VERSION ""

NS_ :

BS_:

BU_: Upper BMS
VAL_TABLE_ operation 132 "操作断路器" 129 "操作继电器" ;
VAL_TABLE_ disable_value 1 "禁止" 0 "允许" ;
VAL_TABLE_ alarm_level2 1 "故障" 0 "正常" ;
VAL_TABLE_ alarm_level 3 "三级告警" 2 "二级告警" 1 "一级故障" 0 "正常" ;
VAL_TABLE_ relay_sts 1 "闭合" 0 "断开" ;
VAL_TABLE_ sys_status 2 "充电" 1 "放电" 0 "空闲" ;

BO_ 2550202728 vol_msg104: 8 BMS
 SG_ cell_vol416 : 48|16@1+ (1,0) [0|65535] "mV" Vector__XXX
 SG_ cell_vol415 : 32|16@1+ (1,0) [0|65535] "mV" Vector__XXX
 SG_ cell_vol414 : 16|16@1+ (1,0) [0|65535] "mV" Vector__XXX
 SG_ cell_vol413 : 0|16@1+ (1,0) [0|65535] "mV" Vector__XXX

BO_ 2550202727 vol_msg103: 8 BMS
 SG_ cell_vol412 : 48|16@1+ (1,0) [0|65535] "mV" Vector__XXX
 SG_ cell_vol411 : 32|16@1+ (1,0) [0|65535] "mV" Vector__XXX
 SG_ cell_vol410 : 16|16@1+ (1,0) [0|65535] "mV" Vector__XXX
 SG_ cell_vol409 : 0|16@1+ (1,0) [0|65535] "mV" Vector__XXX

BO_ 2550202726 vol_msg102: 8 BMS
 SG_ cell_vol408 : 48|16@1+ (1,0) [0|65535] "mV" Vector__XXX
 SG_ cell_vol407 : 32|16@1+ (1,0) [0|65535] "mV" Vector__XXX
 SG_ cell_vol406 : 16|16@1+ (1,0) [0|65535] "mV" Vector__XXX
 SG_ cell_vol405 : 0|16@1+ (1,0) [0|65535] "mV" Vector__XXX

BO_ 2550202725 vol_msg101: 8 BMS
 SG_ cell_vol404 : 48|16@1+ (1,0) [0|65535] "mV" Vector__XXX
 SG_ cell_vol403 : 32|16@1+ (1,0) [0|65535] "mV" Vector__XXX
 SG_ cell_vol402 : 16|16@1+ (1,0) [0|65535] "mV" Vector__XXX
 SG_ cell_vol401 : 0|16@1+ (1,0) [0|65535] "mV" Vector__XXX

BO_ 2550203137 packvol_msg001: 8 Vector__XXX
 SG_ pack_vol4 : 48|16@1+ (10,0) [0|655350] "mV" Vector__XXX
 SG_ pack_vol3 : 32|16@1+ (10,0) [0|655350] "mV" Vector__XXX
 SG_ pack_vol2 : 16|16@1+ (10,0) [0|655350] "mV" Vector__XXX
 SG_ pack_vol1 : 0|16@1+ (10,0) [0|655350] "mV" Vector__XXX

BO_ 2550202383 important_msg15: 8 Vector__XXX
 SG_ bmu_err_id : 0|32@1- (1,0) [0|0] "" Vector__XXX
 SG_ DO_status : 56|1@1- (1,0) [0|0] "" Vector__XXX
 SG_ DI_status : 48|8@1- (1,0) [0|0] "" Vector__XXX

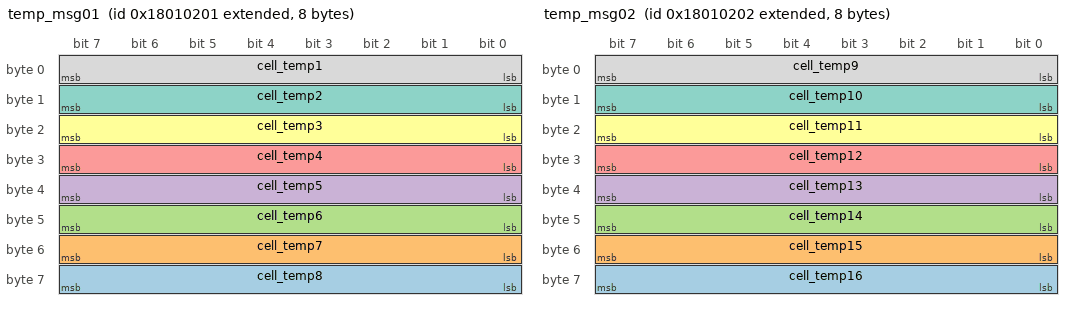
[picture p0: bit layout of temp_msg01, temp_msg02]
BO_ 2550202881 temp_msg01: 8 BMS
 SG_ cell_temp8 : 56|8@1+ (1,-40) [-40|215] "℃" Vector__XXX
 SG_ cell_temp7 : 48|8@1+ (1,-40) [-40|215] "℃" Vector__XXX
 SG_ cell_temp6 : 40|8@1+ (1,-40) [-40|215] "℃" Vector__XXX
 SG_ cell_temp5 : 32|8@1+ (1,-40) [-40|215] "℃" Vector__XXX
 SG_ cell_temp4 : 24|8@1+ (1,-40) [-40|215] "℃" Vector__XXX
 SG_ cell_temp3 : 16|8@1+ (1,-40) [-40|215] "℃" Vector__XXX
 SG_ cell_temp2 : 8|8@1+ (1,-40) [-40|215] "℃" Vector__XXX
 SG_ cell_temp1 : 0|8@1+ (1,-40) [-40|215] "℃" Vector__XXX

BO_ 2550202882 temp_msg02: 8 BMS
 SG_ cell_temp16 : 56|8@1+ (1,-40) [-40|215] "℃" Vector__XXX
 SG_ cell_temp15 : 48|8@1+ (1,-40) [-40|215] "℃" Vector__XXX
 SG_ cell_temp14 : 40|8@1+ (1,-40) [-40|215] "℃" Vector__XXX
 SG_ cell_temp13 : 32|8@1+ (1,-40) [-40|215] "℃" Vector__XXX
 SG_ cell_temp12 : 24|8@1+ (1,-40) [-40|215] "℃" Vector__XXX
 SG_ cell_temp11 : 16|8@1+ (1,-40) [-40|215] "℃" Vector__XXX
 SG_ cell_temp10 : 8|8@1+ (1,-40) [-40|215] "℃" Vector__XXX
 SG_ cell_temp9 : 0|8@1+ (1,-40) [-40|215] "℃" Vector__XXX

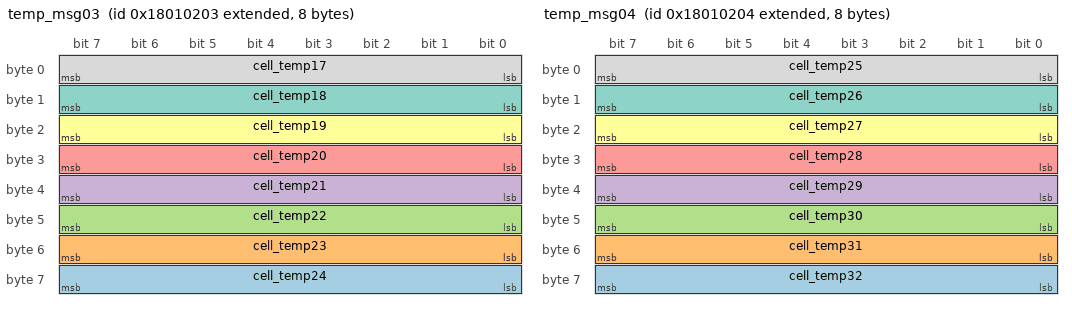
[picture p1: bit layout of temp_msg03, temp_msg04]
BO_ 2550202883 temp_msg03: 8 BMS
 SG_ cell_temp24 : 56|8@1+ (1,-40) [-40|215] "℃" Vector__XXX
 SG_ cell_temp23 : 48|8@1+ (1,-40) [-40|215] "℃" Vector__XXX
 SG_ cell_temp22 : 40|8@1+ (1,-40) [-40|215] "℃" Vector__XXX
 SG_ cell_temp21 : 32|8@1+ (1,-40) [-40|215] "℃" Vector__XXX
 SG_ cell_temp20 : 24|8@1+ (1,-40) [-40|215] "℃" Vector__XXX
 SG_ cell_temp19 : 16|8@1+ (1,-40) [-40|215] "℃" Vector__XXX
 SG_ cell_temp18 : 8|8@1+ (1,-40) [-40|215] "℃" Vector__XXX
 SG_ cell_temp17 : 0|8@1+ (1,-40) [-40|215] "℃" Vector__XXX

BO_ 2550202884 temp_msg04: 8 BMS
 SG_ cell_temp32 : 56|8@1+ (1,-40) [-40|215] "℃" Vector__XXX
 SG_ cell_temp31 : 48|8@1+ (1,-40) [-40|215] "℃" Vector__XXX
 SG_ cell_temp30 : 40|8@1+ (1,-40) [-40|215] "℃" Vector__XXX
 SG_ cell_temp29 : 32|8@1+ (1,-40) [-40|215] "℃" Vector__XXX
 SG_ cell_temp28 : 24|8@1+ (1,-40) [-40|215] "℃" Vector__XXX
 SG_ cell_temp27 : 16|8@1+ (1,-40) [-40|215] "℃" Vector__XXX
 SG_ cell_temp26 : 8|8@1+ (1,-40) [-40|215] "℃" Vector__XXX
 SG_ cell_temp25 : 0|8@1+ (1,-40) [-40|215] "℃" Vector__XXX

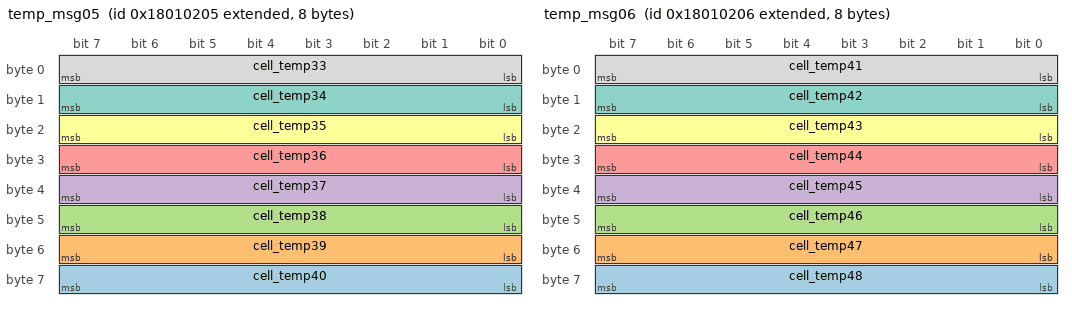
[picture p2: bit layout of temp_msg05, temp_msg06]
BO_ 2550202885 temp_msg05: 8 BMS
 SG_ cell_temp40 : 56|8@1+ (1,-40) [-40|215] "℃" Vector__XXX
 SG_ cell_temp39 : 48|8@1+ (1,-40) [-40|215] "℃" Vector__XXX
 SG_ cell_temp38 : 40|8@1+ (1,-40) [-40|215] "℃" Vector__XXX
 SG_ cell_temp37 : 32|8@1+ (1,-40) [-40|215] "℃" Vector__XXX
 SG_ cell_temp36 : 24|8@1+ (1,-40) [-40|215] "℃" Vector__XXX
 SG_ cell_temp35 : 16|8@1+ (1,-40) [-40|215] "℃" Vector__XXX
 SG_ cell_temp34 : 8|8@1+ (1,-40) [-40|215] "℃" Vector__XXX
 SG_ cell_temp33 : 0|8@1+ (1,-40) [-40|215] "℃" Vector__XXX

BO_ 2550202886 temp_msg06: 8 BMS
 SG_ cell_temp48 : 56|8@1+ (1,-40) [-40|215] "℃" Vector__XXX
 SG_ cell_temp47 : 48|8@1+ (1,-40) [-40|215] "℃" Vector__XXX
 SG_ cell_temp46 : 40|8@1+ (1,-40) [-40|215] "℃" Vector__XXX
 SG_ cell_temp45 : 32|8@1+ (1,-40) [-40|215] "℃" Vector__XXX
 SG_ cell_temp44 : 24|8@1+ (1,-40) [-40|215] "℃" Vector__XXX
 SG_ cell_temp43 : 16|8@1+ (1,-40) [-40|215] "℃" Vector__XXX
 SG_ cell_temp42 : 8|8@1+ (1,-40) [-40|215] "℃" Vector__XXX
 SG_ cell_temp41 : 0|8@1+ (1,-40) [-40|215] "℃" Vector__XXX

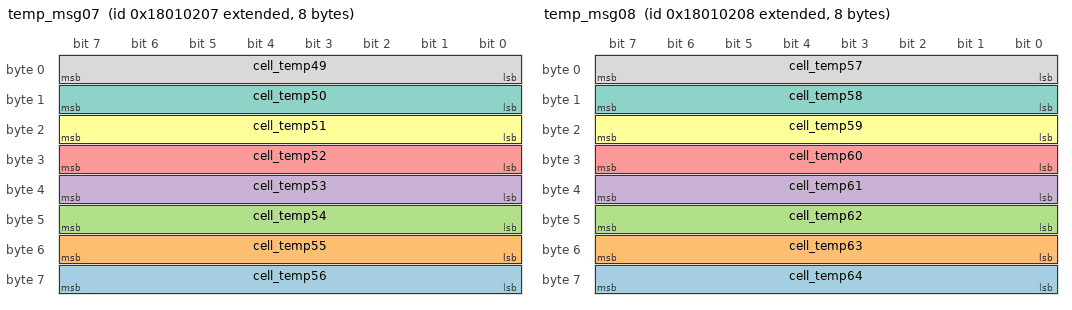
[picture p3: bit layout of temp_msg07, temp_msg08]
BO_ 2550202887 temp_msg07: 8 BMS
 SG_ cell_temp56 : 56|8@1+ (1,-40) [-40|215] "℃" Vector__XXX
 SG_ cell_temp55 : 48|8@1+ (1,-40) [-40|215] "℃" Vector__XXX
 SG_ cell_temp54 : 40|8@1+ (1,-40) [-40|215] "℃" Vector__XXX
 SG_ cell_temp53 : 32|8@1+ (1,-40) [-40|215] "℃" Vector__XXX
 SG_ cell_temp52 : 24|8@1+ (1,-40) [-40|215] "℃" Vector__XXX
 SG_ cell_temp51 : 16|8@1+ (1,-40) [-40|215] "℃" Vector__XXX
 SG_ cell_temp50 : 8|8@1+ (1,-40) [-40|215] "℃" Vector__XXX
 SG_ cell_temp49 : 0|8@1+ (1,-40) [-40|215] "℃" Vector__XXX

BO_ 2550202888 temp_msg08: 8 BMS
 SG_ cell_temp64 : 56|8@1+ (1,-40) [-40|215] "℃" Vector__XXX
 SG_ cell_temp63 : 48|8@1+ (1,-40) [-40|215] "℃" Vector__XXX
 SG_ cell_temp62 : 40|8@1+ (1,-40) [-40|215] "℃" Vector__XXX
 SG_ cell_temp61 : 32|8@1+ (1,-40) [-40|215] "℃" Vector__XXX
 SG_ cell_temp60 : 24|8@1+ (1,-40) [-40|215] "℃" Vector__XXX
 SG_ cell_temp59 : 16|8@1+ (1,-40) [-40|215] "℃" Vector__XXX
 SG_ cell_temp58 : 8|8@1+ (1,-40) [-40|215] "℃" Vector__XXX
 SG_ cell_temp57 : 0|8@1+ (1,-40) [-40|215] "℃" Vector__XXX

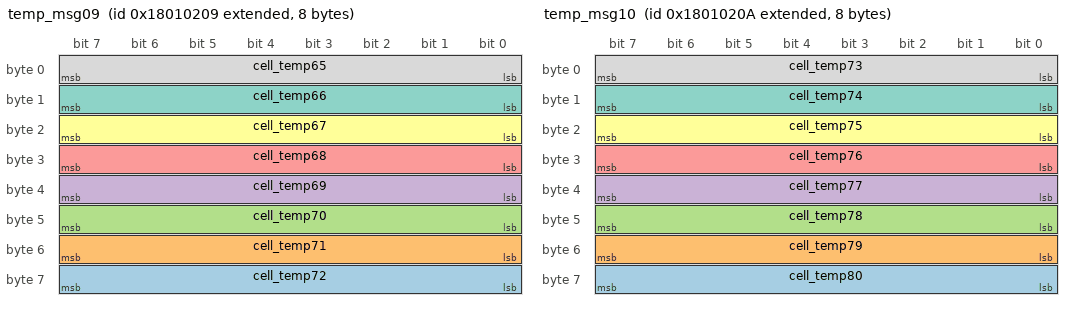
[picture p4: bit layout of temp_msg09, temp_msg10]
BO_ 2550202889 temp_msg09: 8 BMS
 SG_ cell_temp72 : 56|8@1+ (1,-40) [-40|215] "℃" Vector__XXX
 SG_ cell_temp71 : 48|8@1+ (1,-40) [-40|215] "℃" Vector__XXX
 SG_ cell_temp70 : 40|8@1+ (1,-40) [-40|215] "℃" Vector__XXX
 SG_ cell_temp69 : 32|8@1+ (1,-40) [-40|215] "℃" Vector__XXX
 SG_ cell_temp68 : 24|8@1+ (1,-40) [-40|215] "℃" Vector__XXX
 SG_ cell_temp67 : 16|8@1+ (1,-40) [-40|215] "℃" Vector__XXX
 SG_ cell_temp66 : 8|8@1+ (1,-40) [-40|215] "℃" Vector__XXX
 SG_ cell_temp65 : 0|8@1+ (1,-40) [-40|215] "℃" Vector__XXX

BO_ 2550202890 temp_msg10: 8 BMS
 SG_ cell_temp80 : 56|8@1+ (1,-40) [-40|215] "℃" Vector__XXX
 SG_ cell_temp79 : 48|8@1+ (1,-40) [-40|215] "℃" Vector__XXX
 SG_ cell_temp78 : 40|8@1+ (1,-40) [-40|215] "℃" Vector__XXX
 SG_ cell_temp77 : 32|8@1+ (1,-40) [-40|215] "℃" Vector__XXX
 SG_ cell_temp76 : 24|8@1+ (1,-40) [-40|215] "℃" Vector__XXX
 SG_ cell_temp75 : 16|8@1+ (1,-40) [-40|215] "℃" Vector__XXX
 SG_ cell_temp74 : 8|8@1+ (1,-40) [-40|215] "℃" Vector__XXX
 SG_ cell_temp73 : 0|8@1+ (1,-40) [-40|215] "℃" Vector__XXX

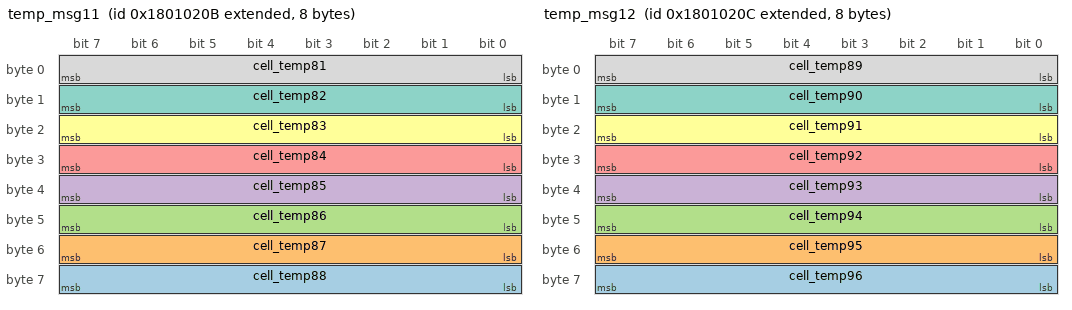
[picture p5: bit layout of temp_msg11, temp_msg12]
BO_ 2550202891 temp_msg11: 8 BMS
 SG_ cell_temp88 : 56|8@1+ (1,-40) [-40|215] "℃" Vector__XXX
 SG_ cell_temp87 : 48|8@1+ (1,-40) [-40|215] "℃" Vector__XXX
 SG_ cell_temp86 : 40|8@1+ (1,-40) [-40|215] "℃" Vector__XXX
 SG_ cell_temp85 : 32|8@1+ (1,-40) [-40|215] "℃" Vector__XXX
 SG_ cell_temp84 : 24|8@1+ (1,-40) [-40|215] "℃" Vector__XXX
 SG_ cell_temp83 : 16|8@1+ (1,-40) [-40|215] "℃" Vector__XXX
 SG_ cell_temp82 : 8|8@1+ (1,-40) [-40|215] "℃" Vector__XXX
 SG_ cell_temp81 : 0|8@1+ (1,-40) [-40|215] "℃" Vector__XXX

BO_ 2550202892 temp_msg12: 8 BMS
 SG_ cell_temp96 : 56|8@1+ (1,-40) [-40|215] "℃" Vector__XXX
 SG_ cell_temp95 : 48|8@1+ (1,-40) [-40|215] "℃" Vector__XXX
 SG_ cell_temp94 : 40|8@1+ (1,-40) [-40|215] "℃" Vector__XXX
 SG_ cell_temp93 : 32|8@1+ (1,-40) [-40|215] "℃" Vector__XXX
 SG_ cell_temp92 : 24|8@1+ (1,-40) [-40|215] "℃" Vector__XXX
 SG_ cell_temp91 : 16|8@1+ (1,-40) [-40|215] "℃" Vector__XXX
 SG_ cell_temp90 : 8|8@1+ (1,-40) [-40|215] "℃" Vector__XXX
 SG_ cell_temp89 : 0|8@1+ (1,-40) [-40|215] "℃" Vector__XXX

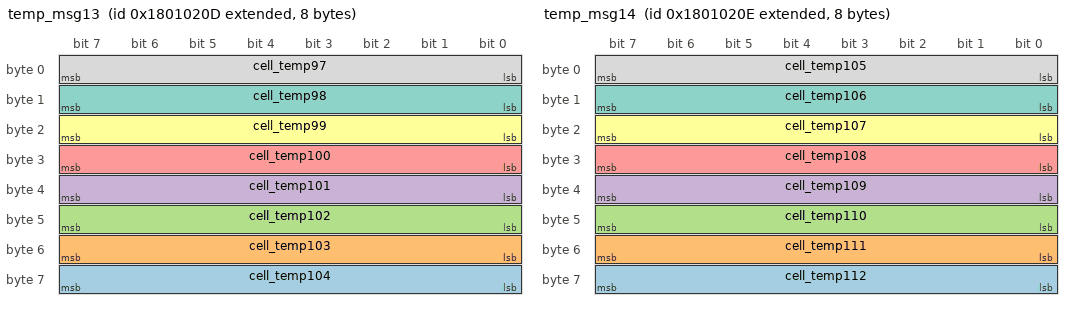
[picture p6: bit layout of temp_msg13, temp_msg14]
BO_ 2550202893 temp_msg13: 8 BMS
 SG_ cell_temp104 : 56|8@1+ (1,-40) [-40|215] "℃" Vector__XXX
 SG_ cell_temp103 : 48|8@1+ (1,-40) [-40|215] "℃" Vector__XXX
 SG_ cell_temp102 : 40|8@1+ (1,-40) [-40|215] "℃" Vector__XXX
 SG_ cell_temp101 : 32|8@1+ (1,-40) [-40|215] "℃" Vector__XXX
 SG_ cell_temp100 : 24|8@1+ (1,-40) [-40|215] "℃" Vector__XXX
 SG_ cell_temp99 : 16|8@1+ (1,-40) [-40|215] "℃" Vector__XXX
 SG_ cell_temp98 : 8|8@1+ (1,-40) [-40|215] "℃" Vector__XXX
 SG_ cell_temp97 : 0|8@1+ (1,-40) [-40|215] "℃" Vector__XXX

BO_ 2550202894 temp_msg14: 8 BMS
 SG_ cell_temp112 : 56|8@1+ (1,-40) [-40|215] "℃" Vector__XXX
 SG_ cell_temp111 : 48|8@1+ (1,-40) [-40|215] "℃" Vector__XXX
 SG_ cell_temp110 : 40|8@1+ (1,-40) [-40|215] "℃" Vector__XXX
 SG_ cell_temp109 : 32|8@1+ (1,-40) [-40|215] "℃" Vector__XXX
 SG_ cell_temp108 : 24|8@1+ (1,-40) [-40|215] "℃" Vector__XXX
 SG_ cell_temp107 : 16|8@1+ (1,-40) [-40|215] "℃" Vector__XXX
 SG_ cell_temp106 : 8|8@1+ (1,-40) [-40|215] "℃" Vector__XXX
 SG_ cell_temp105 : 0|8@1+ (1,-40) [-40|215] "℃" Vector__XXX

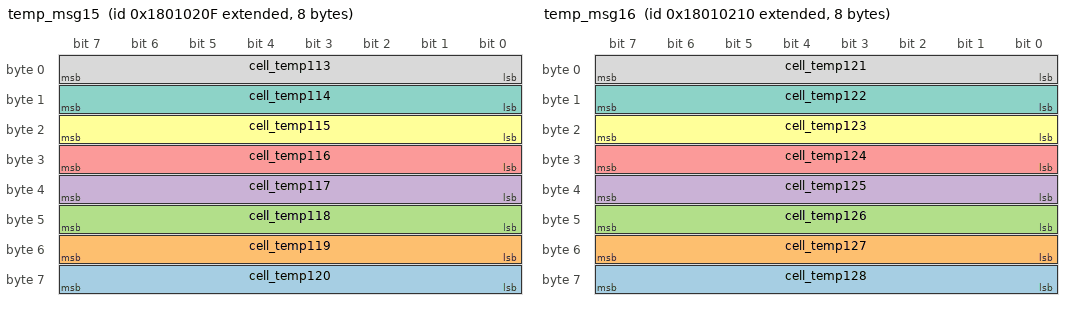
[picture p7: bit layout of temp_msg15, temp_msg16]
BO_ 2550202895 temp_msg15: 8 BMS
 SG_ cell_temp120 : 56|8@1+ (1,-40) [-40|215] "℃" Vector__XXX
 SG_ cell_temp119 : 48|8@1+ (1,-40) [-40|215] "℃" Vector__XXX
 SG_ cell_temp118 : 40|8@1+ (1,-40) [-40|215] "℃" Vector__XXX
 SG_ cell_temp117 : 32|8@1+ (1,-40) [-40|215] "℃" Vector__XXX
 SG_ cell_temp116 : 24|8@1+ (1,-40) [-40|215] "℃" Vector__XXX
 SG_ cell_temp115 : 16|8@1+ (1,-40) [-40|215] "℃" Vector__XXX
 SG_ cell_temp114 : 8|8@1+ (1,-40) [-40|215] "℃" Vector__XXX
 SG_ cell_temp113 : 0|8@1+ (1,-40) [-40|215] "℃" Vector__XXX

BO_ 2550202896 temp_msg16: 8 BMS
 SG_ cell_temp128 : 56|8@1+ (1,-40) [-40|215] "℃" Vector__XXX
 SG_ cell_temp127 : 48|8@1+ (1,-40) [-40|215] "℃" Vector__XXX
 SG_ cell_temp126 : 40|8@1+ (1,-40) [-40|215] "℃" Vector__XXX
 SG_ cell_temp125 : 32|8@1+ (1,-40) [-40|215] "℃" Vector__XXX
 SG_ cell_temp124 : 24|8@1+ (1,-40) [-40|215] "℃" Vector__XXX
 SG_ cell_temp123 : 16|8@1+ (1,-40) [-40|215] "℃" Vector__XXX
 SG_ cell_temp122 : 8|8@1+ (1,-40) [-40|215] "℃" Vector__XXX
 SG_ cell_temp121 : 0|8@1+ (1,-40) [-40|215] "℃" Vector__XXX

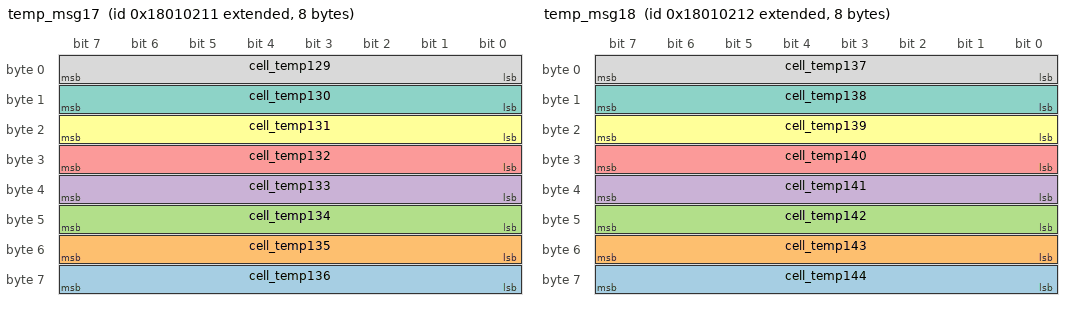
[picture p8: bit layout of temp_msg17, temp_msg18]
BO_ 2550202897 temp_msg17: 8 BMS
 SG_ cell_temp136 : 56|8@1+ (1,-40) [-40|215] "℃" Vector__XXX
 SG_ cell_temp135 : 48|8@1+ (1,-40) [-40|215] "℃" Vector__XXX
 SG_ cell_temp134 : 40|8@1+ (1,-40) [-40|215] "℃" Vector__XXX
 SG_ cell_temp133 : 32|8@1+ (1,-40) [-40|215] "℃" Vector__XXX
 SG_ cell_temp132 : 24|8@1+ (1,-40) [-40|215] "℃" Vector__XXX
 SG_ cell_temp131 : 16|8@1+ (1,-40) [-40|215] "℃" Vector__XXX
 SG_ cell_temp130 : 8|8@1+ (1,-40) [-40|215] "℃" Vector__XXX
 SG_ cell_temp129 : 0|8@1+ (1,-40) [-40|215] "℃" Vector__XXX

BO_ 2550202898 temp_msg18: 8 BMS
 SG_ cell_temp144 : 56|8@1+ (1,-40) [-40|215] "℃" Vector__XXX
 SG_ cell_temp143 : 48|8@1+ (1,-40) [-40|215] "℃" Vector__XXX
 SG_ cell_temp142 : 40|8@1+ (1,-40) [-40|215] "℃" Vector__XXX
 SG_ cell_temp141 : 32|8@1+ (1,-40) [-40|215] "℃" Vector__XXX
 SG_ cell_temp140 : 24|8@1+ (1,-40) [-40|215] "℃" Vector__XXX
 SG_ cell_temp139 : 16|8@1+ (1,-40) [-40|215] "℃" Vector__XXX
 SG_ cell_temp138 : 8|8@1+ (1,-40) [-40|215] "℃" Vector__XXX
 SG_ cell_temp137 : 0|8@1+ (1,-40) [-40|215] "℃" Vector__XXX

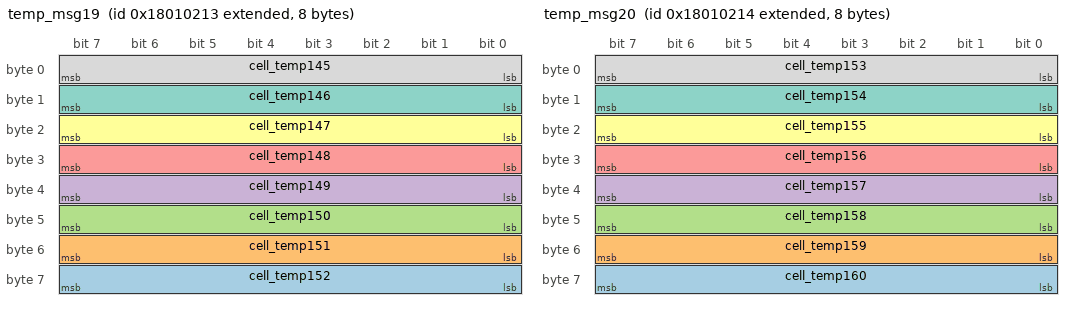
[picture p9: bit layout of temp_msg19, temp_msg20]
BO_ 2550202899 temp_msg19: 8 BMS
 SG_ cell_temp152 : 56|8@1+ (1,-40) [-40|215] "℃" Vector__XXX
 SG_ cell_temp151 : 48|8@1+ (1,-40) [-40|215] "℃" Vector__XXX
 SG_ cell_temp150 : 40|8@1+ (1,-40) [-40|215] "℃" Vector__XXX
 SG_ cell_temp149 : 32|8@1+ (1,-40) [-40|215] "℃" Vector__XXX
 SG_ cell_temp148 : 24|8@1+ (1,-40) [-40|215] "℃" Vector__XXX
 SG_ cell_temp147 : 16|8@1+ (1,-40) [-40|215] "℃" Vector__XXX
 SG_ cell_temp146 : 8|8@1+ (1,-40) [-40|215] "℃" Vector__XXX
 SG_ cell_temp145 : 0|8@1+ (1,-40) [-40|215] "℃" Vector__XXX

BO_ 2550202900 temp_msg20: 8 BMS
 SG_ cell_temp160 : 56|8@1+ (1,-40) [-40|215] "℃" Vector__XXX
 SG_ cell_temp159 : 48|8@1+ (1,-40) [-40|215] "℃" Vector__XXX
 SG_ cell_temp158 : 40|8@1+ (1,-40) [-40|215] "℃" Vector__XXX
 SG_ cell_temp157 : 32|8@1+ (1,-40) [-40|215] "℃" Vector__XXX
 SG_ cell_temp156 : 24|8@1+ (1,-40) [-40|215] "℃" Vector__XXX
 SG_ cell_temp155 : 16|8@1+ (1,-40) [-40|215] "℃" Vector__XXX
 SG_ cell_temp154 : 8|8@1+ (1,-40) [-40|215] "℃" Vector__XXX
 SG_ cell_temp153 : 0|8@1+ (1,-40) [-40|215] "℃" Vector__XXX

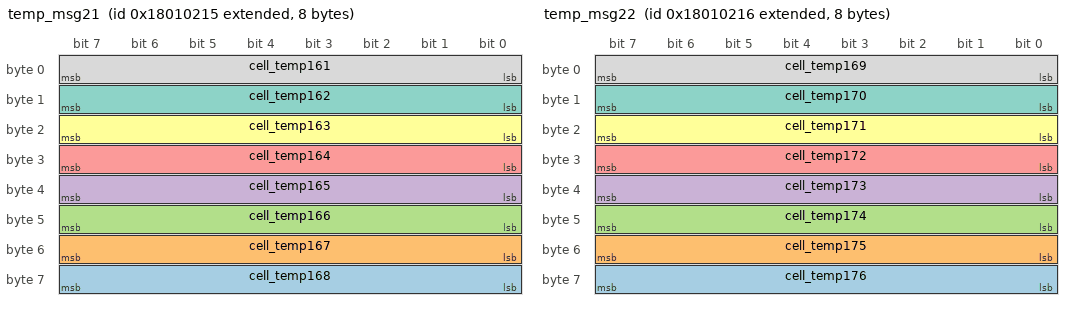
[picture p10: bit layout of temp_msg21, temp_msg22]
BO_ 2550202901 temp_msg21: 8 BMS
 SG_ cell_temp168 : 56|8@1+ (1,-40) [-40|215] "℃" Vector__XXX
 SG_ cell_temp167 : 48|8@1+ (1,-40) [-40|215] "℃" Vector__XXX
 SG_ cell_temp166 : 40|8@1+ (1,-40) [-40|215] "℃" Vector__XXX
 SG_ cell_temp165 : 32|8@1+ (1,-40) [-40|215] "℃" Vector__XXX
 SG_ cell_temp164 : 24|8@1+ (1,-40) [-40|215] "℃" Vector__XXX
 SG_ cell_temp163 : 16|8@1+ (1,-40) [-40|215] "℃" Vector__XXX
 SG_ cell_temp162 : 8|8@1+ (1,-40) [-40|215] "℃" Vector__XXX
 SG_ cell_temp161 : 0|8@1+ (1,-40) [-40|215] "℃" Vector__XXX

BO_ 2550202902 temp_msg22: 8 BMS
 SG_ cell_temp176 : 56|8@1+ (1,-40) [-40|215] "℃" Vector__XXX
 SG_ cell_temp175 : 48|8@1+ (1,-40) [-40|215] "℃" Vector__XXX
 SG_ cell_temp174 : 40|8@1+ (1,-40) [-40|215] "℃" Vector__XXX
 SG_ cell_temp173 : 32|8@1+ (1,-40) [-40|215] "℃" Vector__XXX
 SG_ cell_temp172 : 24|8@1+ (1,-40) [-40|215] "℃" Vector__XXX
 SG_ cell_temp171 : 16|8@1+ (1,-40) [-40|215] "℃" Vector__XXX
 SG_ cell_temp170 : 8|8@1+ (1,-40) [-40|215] "℃" Vector__XXX
 SG_ cell_temp169 : 0|8@1+ (1,-40) [-40|215] "℃" Vector__XXX

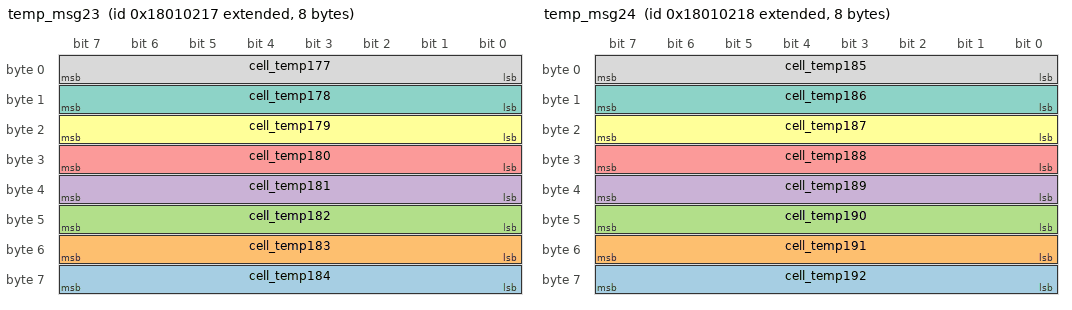
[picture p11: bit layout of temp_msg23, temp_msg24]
BO_ 2550202903 temp_msg23: 8 BMS
 SG_ cell_temp184 : 56|8@1+ (1,-40) [-40|215] "℃" Vector__XXX
 SG_ cell_temp183 : 48|8@1+ (1,-40) [-40|215] "℃" Vector__XXX
 SG_ cell_temp182 : 40|8@1+ (1,-40) [-40|215] "℃" Vector__XXX
 SG_ cell_temp181 : 32|8@1+ (1,-40) [-40|215] "℃" Vector__XXX
 SG_ cell_temp180 : 24|8@1+ (1,-40) [-40|215] "℃" Vector__XXX
 SG_ cell_temp179 : 16|8@1+ (1,-40) [-40|215] "℃" Vector__XXX
 SG_ cell_temp178 : 8|8@1+ (1,-40) [-40|215] "℃" Vector__XXX
 SG_ cell_temp177 : 0|8@1+ (1,-40) [-40|215] "℃" Vector__XXX

BO_ 2550202904 temp_msg24: 8 BMS
 SG_ cell_temp192 : 56|8@1+ (1,-40) [-40|215] "℃" Vector__XXX
 SG_ cell_temp191 : 48|8@1+ (1,-40) [-40|215] "℃" Vector__XXX
 SG_ cell_temp190 : 40|8@1+ (1,-40) [-40|215] "℃" Vector__XXX
 SG_ cell_temp189 : 32|8@1+ (1,-40) [-40|215] "℃" Vector__XXX
 SG_ cell_temp188 : 24|8@1+ (1,-40) [-40|215] "℃" Vector__XXX
 SG_ cell_temp187 : 16|8@1+ (1,-40) [-40|215] "℃" Vector__XXX
 SG_ cell_temp186 : 8|8@1+ (1,-40) [-40|215] "℃" Vector__XXX
 SG_ cell_temp185 : 0|8@1+ (1,-40) [-40|215] "℃" Vector__XXX

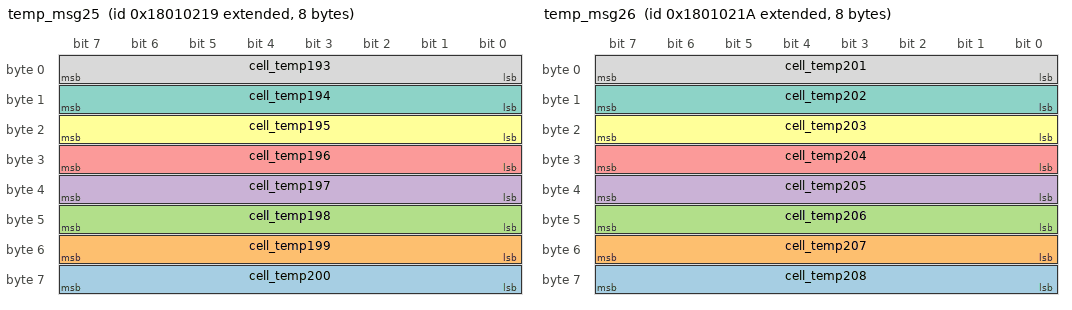
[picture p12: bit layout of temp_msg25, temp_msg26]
BO_ 2550202905 temp_msg25: 8 BMS
 SG_ cell_temp200 : 56|8@1+ (1,-40) [-40|215] "℃" Vector__XXX
 SG_ cell_temp199 : 48|8@1+ (1,-40) [-40|215] "℃" Vector__XXX
 SG_ cell_temp198 : 40|8@1+ (1,-40) [-40|215] "℃" Vector__XXX
 SG_ cell_temp197 : 32|8@1+ (1,-40) [-40|215] "℃" Vector__XXX
 SG_ cell_temp196 : 24|8@1+ (1,-40) [-40|215] "℃" Vector__XXX
 SG_ cell_temp195 : 16|8@1+ (1,-40) [-40|215] "℃" Vector__XXX
 SG_ cell_temp194 : 8|8@1+ (1,-40) [-40|215] "℃" Vector__XXX
 SG_ cell_temp193 : 0|8@1+ (1,-40) [-40|215] "℃" Vector__XXX

BO_ 2550202906 temp_msg26: 8 BMS
 SG_ cell_temp208 : 56|8@1+ (1,-40) [-40|215] "℃" Vector__XXX
 SG_ cell_temp207 : 48|8@1+ (1,-40) [-40|215] "℃" Vector__XXX
 SG_ cell_temp206 : 40|8@1+ (1,-40) [-40|215] "℃" Vector__XXX
 SG_ cell_temp205 : 32|8@1+ (1,-40) [-40|215] "℃" Vector__XXX
 SG_ cell_temp204 : 24|8@1+ (1,-40) [-40|215] "℃" Vector__XXX
 SG_ cell_temp203 : 16|8@1+ (1,-40) [-40|215] "℃" Vector__XXX
 SG_ cell_temp202 : 8|8@1+ (1,-40) [-40|215] "℃" Vector__XXX
 SG_ cell_temp201 : 0|8@1+ (1,-40) [-40|215] "℃" Vector__XXX

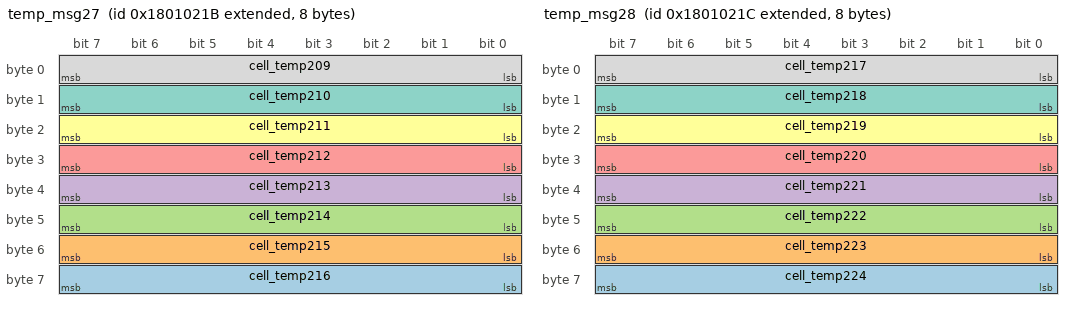
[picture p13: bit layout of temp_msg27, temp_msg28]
BO_ 2550202907 temp_msg27: 8 BMS
 SG_ cell_temp216 : 56|8@1+ (1,-40) [-40|215] "℃" Vector__XXX
 SG_ cell_temp215 : 48|8@1+ (1,-40) [-40|215] "℃" Vector__XXX
 SG_ cell_temp214 : 40|8@1+ (1,-40) [-40|215] "℃" Vector__XXX
 SG_ cell_temp213 : 32|8@1+ (1,-40) [-40|215] "℃" Vector__XXX
 SG_ cell_temp212 : 24|8@1+ (1,-40) [-40|215] "℃" Vector__XXX
 SG_ cell_temp211 : 16|8@1+ (1,-40) [-40|215] "℃" Vector__XXX
 SG_ cell_temp210 : 8|8@1+ (1,-40) [-40|215] "℃" Vector__XXX
 SG_ cell_temp209 : 0|8@1+ (1,-40) [-40|215] "℃" Vector__XXX

BO_ 2550202908 temp_msg28: 8 BMS
 SG_ cell_temp224 : 56|8@1+ (1,-40) [-40|215] "℃" Vector__XXX
 SG_ cell_temp223 : 48|8@1+ (1,-40) [-40|215] "℃" Vector__XXX
 SG_ cell_temp222 : 40|8@1+ (1,-40) [-40|215] "℃" Vector__XXX
 SG_ cell_temp221 : 32|8@1+ (1,-40) [-40|215] "℃" Vector__XXX
 SG_ cell_temp220 : 24|8@1+ (1,-40) [-40|215] "℃" Vector__XXX
 SG_ cell_temp219 : 16|8@1+ (1,-40) [-40|215] "℃" Vector__XXX
 SG_ cell_temp218 : 8|8@1+ (1,-40) [-40|215] "℃" Vector__XXX
 SG_ cell_temp217 : 0|8@1+ (1,-40) [-40|215] "℃" Vector__XXX

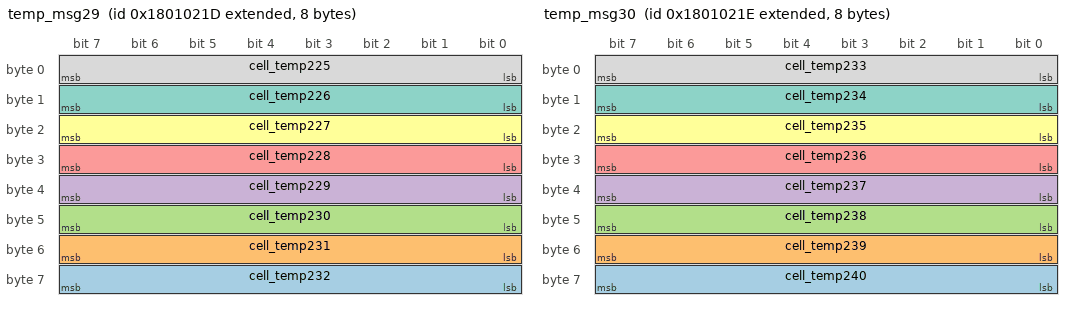
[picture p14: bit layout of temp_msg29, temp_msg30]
BO_ 2550202909 temp_msg29: 8 BMS
 SG_ cell_temp232 : 56|8@1+ (1,-40) [-40|215] "℃" Vector__XXX
 SG_ cell_temp231 : 48|8@1+ (1,-40) [-40|215] "℃" Vector__XXX
 SG_ cell_temp230 : 40|8@1+ (1,-40) [-40|215] "℃" Vector__XXX
 SG_ cell_temp229 : 32|8@1+ (1,-40) [-40|215] "℃" Vector__XXX
 SG_ cell_temp228 : 24|8@1+ (1,-40) [-40|215] "℃" Vector__XXX
 SG_ cell_temp227 : 16|8@1+ (1,-40) [-40|215] "℃" Vector__XXX
 SG_ cell_temp226 : 8|8@1+ (1,-40) [-40|215] "℃" Vector__XXX
 SG_ cell_temp225 : 0|8@1+ (1,-40) [-40|215] "℃" Vector__XXX

BO_ 2550202910 temp_msg30: 8 BMS
 SG_ cell_temp240 : 56|8@1+ (1,-40) [-40|215] "℃" Vector__XXX
 SG_ cell_temp239 : 48|8@1+ (1,-40) [-40|215] "℃" Vector__XXX
 SG_ cell_temp238 : 40|8@1+ (1,-40) [-40|215] "℃" Vector__XXX
 SG_ cell_temp237 : 32|8@1+ (1,-40) [-40|215] "℃" Vector__XXX
 SG_ cell_temp236 : 24|8@1+ (1,-40) [-40|215] "℃" Vector__XXX
 SG_ cell_temp235 : 16|8@1+ (1,-40) [-40|215] "℃" Vector__XXX
 SG_ cell_temp234 : 8|8@1+ (1,-40) [-40|215] "℃" Vector__XXX
 SG_ cell_temp233 : 0|8@1+ (1,-40) [-40|215] "℃" Vector__XXX

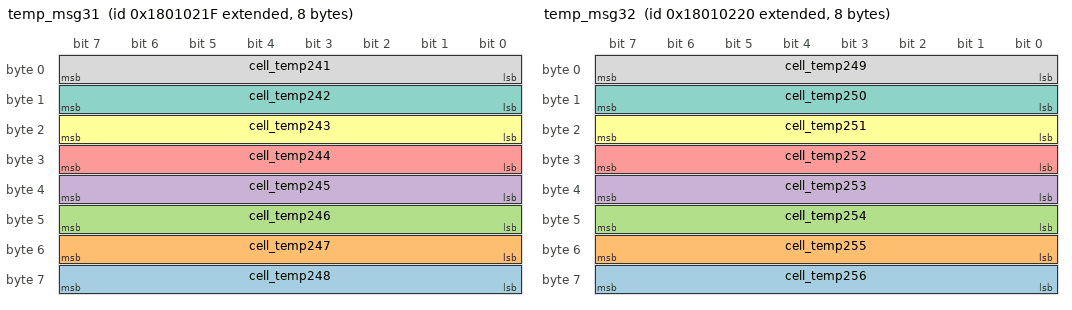
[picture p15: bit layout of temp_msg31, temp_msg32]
BO_ 2550202911 temp_msg31: 8 BMS
 SG_ cell_temp248 : 56|8@1+ (1,-40) [-40|215] "℃" Vector__XXX
 SG_ cell_temp247 : 48|8@1+ (1,-40) [-40|215] "℃" Vector__XXX
 SG_ cell_temp246 : 40|8@1+ (1,-40) [-40|215] "℃" Vector__XXX
 SG_ cell_temp245 : 32|8@1+ (1,-40) [-40|215] "℃" Vector__XXX
 SG_ cell_temp244 : 24|8@1+ (1,-40) [-40|215] "℃" Vector__XXX
 SG_ cell_temp243 : 16|8@1+ (1,-40) [-40|215] "℃" Vector__XXX
 SG_ cell_temp242 : 8|8@1+ (1,-40) [-40|215] "℃" Vector__XXX
 SG_ cell_temp241 : 0|8@1+ (1,-40) [-40|215] "℃" Vector__XXX

BO_ 2550202912 temp_msg32: 8 BMS
 SG_ cell_temp256 : 56|8@1+ (1,-40) [-40|215] "℃" Vector__XXX
 SG_ cell_temp255 : 48|8@1+ (1,-40) [-40|215] "℃" Vector__XXX
 SG_ cell_temp254 : 40|8@1+ (1,-40) [-40|215] "℃" Vector__XXX
 SG_ cell_temp253 : 32|8@1+ (1,-40) [-40|215] "℃" Vector__XXX
 SG_ cell_temp252 : 24|8@1+ (1,-40) [-40|215] "℃" Vector__XXX
 SG_ cell_temp251 : 16|8@1+ (1,-40) [-40|215] "℃" Vector__XXX
 SG_ cell_temp250 : 8|8@1+ (1,-40) [-40|215] "℃" Vector__XXX
 SG_ cell_temp249 : 0|8@1+ (1,-40) [-40|215] "℃" Vector__XXX

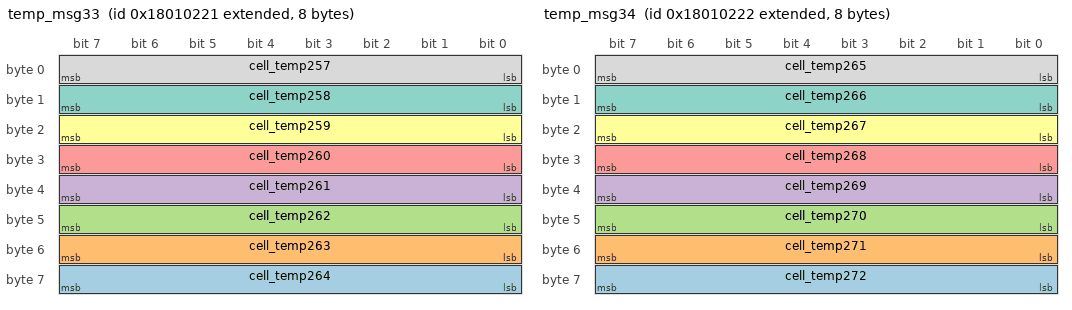
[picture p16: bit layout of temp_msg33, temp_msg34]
BO_ 2550202913 temp_msg33: 8 BMS
 SG_ cell_temp264 : 56|8@1+ (1,-40) [-40|215] "℃" Vector__XXX
 SG_ cell_temp263 : 48|8@1+ (1,-40) [-40|215] "℃" Vector__XXX
 SG_ cell_temp262 : 40|8@1+ (1,-40) [-40|215] "℃" Vector__XXX
 SG_ cell_temp261 : 32|8@1+ (1,-40) [-40|215] "℃" Vector__XXX
 SG_ cell_temp260 : 24|8@1+ (1,-40) [-40|215] "℃" Vector__XXX
 SG_ cell_temp259 : 16|8@1+ (1,-40) [-40|215] "℃" Vector__XXX
 SG_ cell_temp258 : 8|8@1+ (1,-40) [-40|215] "℃" Vector__XXX
 SG_ cell_temp257 : 0|8@1+ (1,-40) [-40|215] "℃" Vector__XXX

BO_ 2550202914 temp_msg34: 8 BMS
 SG_ cell_temp272 : 56|8@1+ (1,-40) [-40|215] "℃" Vector__XXX
 SG_ cell_temp271 : 48|8@1+ (1,-40) [-40|215] "℃" Vector__XXX
 SG_ cell_temp270 : 40|8@1+ (1,-40) [-40|215] "℃" Vector__XXX
 SG_ cell_temp269 : 32|8@1+ (1,-40) [-40|215] "℃" Vector__XXX
 SG_ cell_temp268 : 24|8@1+ (1,-40) [-40|215] "℃" Vector__XXX
 SG_ cell_temp267 : 16|8@1+ (1,-40) [-40|215] "℃" Vector__XXX
 SG_ cell_temp266 : 8|8@1+ (1,-40) [-40|215] "℃" Vector__XXX
 SG_ cell_temp265 : 0|8@1+ (1,-40) [-40|215] "℃" Vector__XXX

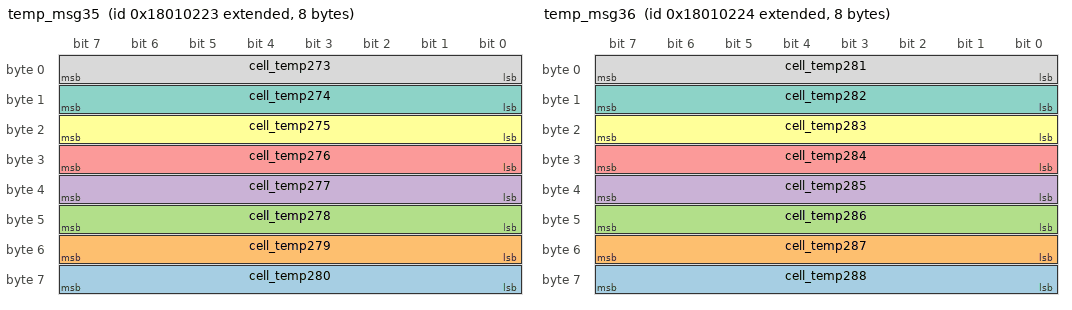
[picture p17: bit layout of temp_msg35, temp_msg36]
BO_ 2550202915 temp_msg35: 8 BMS
 SG_ cell_temp280 : 56|8@1+ (1,-40) [-40|215] "℃" Vector__XXX
 SG_ cell_temp279 : 48|8@1+ (1,-40) [-40|215] "℃" Vector__XXX
 SG_ cell_temp278 : 40|8@1+ (1,-40) [-40|215] "℃" Vector__XXX
 SG_ cell_temp277 : 32|8@1+ (1,-40) [-40|215] "℃" Vector__XXX
 SG_ cell_temp276 : 24|8@1+ (1,-40) [-40|215] "℃" Vector__XXX
 SG_ cell_temp275 : 16|8@1+ (1,-40) [-40|215] "℃" Vector__XXX
 SG_ cell_temp274 : 8|8@1+ (1,-40) [-40|215] "℃" Vector__XXX
 SG_ cell_temp273 : 0|8@1+ (1,-40) [-40|215] "℃" Vector__XXX

BO_ 2550202916 temp_msg36: 8 BMS
 SG_ cell_temp288 : 56|8@1+ (1,-40) [-40|215] "℃" Vector__XXX
 SG_ cell_temp287 : 48|8@1+ (1,-40) [-40|215] "℃" Vector__XXX
 SG_ cell_temp286 : 40|8@1+ (1,-40) [-40|215] "℃" Vector__XXX
 SG_ cell_temp285 : 32|8@1+ (1,-40) [-40|215] "℃" Vector__XXX
 SG_ cell_temp284 : 24|8@1+ (1,-40) [-40|215] "℃" Vector__XXX
 SG_ cell_temp283 : 16|8@1+ (1,-40) [-40|215] "℃" Vector__XXX
 SG_ cell_temp282 : 8|8@1+ (1,-40) [-40|215] "℃" Vector__XXX
 SG_ cell_temp281 : 0|8@1+ (1,-40) [-40|215] "℃" Vector__XXX

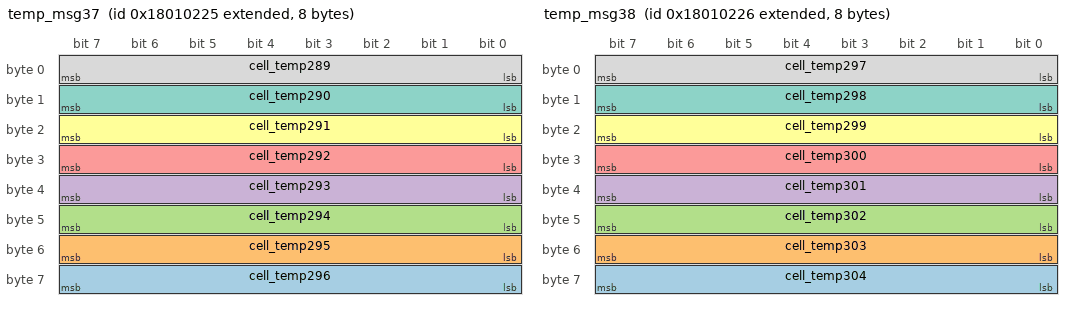
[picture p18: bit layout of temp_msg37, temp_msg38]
BO_ 2550202917 temp_msg37: 8 BMS
 SG_ cell_temp296 : 56|8@1+ (1,-40) [-40|215] "℃" Vector__XXX
 SG_ cell_temp295 : 48|8@1+ (1,-40) [-40|215] "℃" Vector__XXX
 SG_ cell_temp294 : 40|8@1+ (1,-40) [-40|215] "℃" Vector__XXX
 SG_ cell_temp293 : 32|8@1+ (1,-40) [-40|215] "℃" Vector__XXX
 SG_ cell_temp292 : 24|8@1+ (1,-40) [-40|215] "℃" Vector__XXX
 SG_ cell_temp291 : 16|8@1+ (1,-40) [-40|215] "℃" Vector__XXX
 SG_ cell_temp290 : 8|8@1+ (1,-40) [-40|215] "℃" Vector__XXX
 SG_ cell_temp289 : 0|8@1+ (1,-40) [-40|215] "℃" Vector__XXX

BO_ 2550202918 temp_msg38: 8 BMS
 SG_ cell_temp304 : 56|8@1+ (1,-40) [-40|215] "℃" Vector__XXX
 SG_ cell_temp303 : 48|8@1+ (1,-40) [-40|215] "℃" Vector__XXX
 SG_ cell_temp302 : 40|8@1+ (1,-40) [-40|215] "℃" Vector__XXX
 SG_ cell_temp301 : 32|8@1+ (1,-40) [-40|215] "℃" Vector__XXX
 SG_ cell_temp300 : 24|8@1+ (1,-40) [-40|215] "℃" Vector__XXX
 SG_ cell_temp299 : 16|8@1+ (1,-40) [-40|215] "℃" Vector__XXX
 SG_ cell_temp298 : 8|8@1+ (1,-40) [-40|215] "℃" Vector__XXX
 SG_ cell_temp297 : 0|8@1+ (1,-40) [-40|215] "℃" Vector__XXX

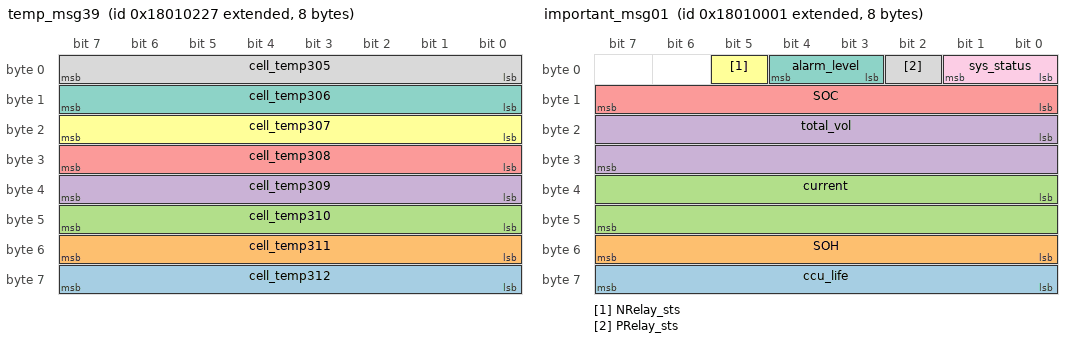
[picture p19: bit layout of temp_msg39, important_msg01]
BO_ 2550202919 temp_msg39: 8 BMS
 SG_ cell_temp312 : 56|8@1+ (1,-40) [-40|215] "℃" Vector__XXX
 SG_ cell_temp311 : 48|8@1+ (1,-40) [-40|215] "℃" Vector__XXX
 SG_ cell_temp310 : 40|8@1+ (1,-40) [-40|215] "℃" Vector__XXX
 SG_ cell_temp309 : 32|8@1+ (1,-40) [-40|215] "℃" Vector__XXX
 SG_ cell_temp308 : 24|8@1+ (1,-40) [-40|215] "℃" Vector__XXX
 SG_ cell_temp307 : 16|8@1+ (1,-40) [-40|215] "℃" Vector__XXX
 SG_ cell_temp306 : 8|8@1+ (1,-40) [-40|215] "℃" Vector__XXX
 SG_ cell_temp305 : 0|8@1+ (1,-40) [-40|215] "℃" Vector__XXX

BO_ 2550202920 temp_msg40: 8 BMS
 SG_ cell_temp320 : 56|8@1+ (1,-40) [-40|215] "℃" Vector__XXX
 SG_ cell_temp319 : 48|8@1+ (1,-40) [-40|215] "℃" Vector__XXX
 SG_ cell_temp318 : 40|8@1+ (1,-40) [-40|215] "℃" Vector__XXX
 SG_ cell_temp317 : 32|8@1+ (1,-40) [-40|215] "℃" Vector__XXX
 SG_ cell_temp316 : 24|8@1+ (1,-40) [-40|215] "℃" Vector__XXX
 SG_ cell_temp315 : 16|8@1+ (1,-40) [-40|215] "℃" Vector__XXX
 SG_ cell_temp314 : 8|8@1+ (1,-40) [-40|215] "℃" Vector__XXX
 SG_ cell_temp313 : 0|8@1+ (1,-40) [-40|215] "℃" Vector__XXX

BO_ 2550202921 temp_msg41: 8 BMS
 SG_ cell_temp328 : 56|8@1+ (1,-40) [-40|215] "℃" Vector__XXX
 SG_ cell_temp327 : 48|8@1+ (1,-40) [-40|215] "℃" Vector__XXX
 SG_ cell_temp326 : 40|8@1+ (1,-40) [-40|215] "℃" Vector__XXX
 SG_ cell_temp325 : 32|8@1+ (1,-40) [-40|215] "℃" Vector__XXX
 SG_ cell_temp324 : 24|8@1+ (1,-40) [-40|215] "℃" Vector__XXX
 SG_ cell_temp323 : 16|8@1+ (1,-40) [-40|215] "℃" Vector__XXX
 SG_ cell_temp322 : 8|8@1+ (1,-40) [-40|215] "℃" Vector__XXX
 SG_ cell_temp321 : 0|8@1+ (1,-40) [-40|215] "℃" Vector__XXX

BO_ 2550202922 temp_msg42: 8 BMS
 SG_ cell_temp336 : 56|8@1+ (1,-40) [-40|215] "℃" Vector__XXX
 SG_ cell_temp335 : 48|8@1+ (1,-40) [-40|215] "℃" Vector__XXX
 SG_ cell_temp334 : 40|8@1+ (1,-40) [-40|215] "℃" Vector__XXX
 SG_ cell_temp333 : 32|8@1+ (1,-40) [-40|215] "℃" Vector__XXX
 SG_ cell_temp332 : 24|8@1+ (1,-40) [-40|215] "℃" Vector__XXX
 SG_ cell_temp331 : 16|8@1+ (1,-40) [-40|215] "℃" Vector__XXX
 SG_ cell_temp330 : 8|8@1+ (1,-40) [-40|215] "℃" Vector__XXX
 SG_ cell_temp329 : 0|8@1+ (1,-40) [-40|215] "℃" Vector__XXX

BO_ 2550202923 temp_msg43: 8 BMS
 SG_ cell_temp344 : 56|8@1+ (1,-40) [-40|215] "℃" Vector__XXX
 SG_ cell_temp343 : 48|8@1+ (1,-40) [-40|215] "℃" Vector__XXX
 SG_ cell_temp342 : 40|8@1+ (1,-40) [-40|215] "℃" Vector__XXX
 SG_ cell_temp341 : 32|8@1+ (1,-40) [-40|215] "℃" Vector__XXX
 SG_ cell_temp340 : 24|8@1+ (1,-40) [-40|215] "℃" Vector__XXX
 SG_ cell_temp339 : 16|8@1+ (1,-40) [-40|215] "℃" Vector__XXX
 SG_ cell_temp338 : 8|8@1+ (1,-40) [-40|215] "℃" Vector__XXX
 SG_ cell_temp337 : 0|8@1+ (1,-40) [-40|215] "℃" Vector__XXX

BO_ 2550202924 temp_msg44: 8 BMS
 SG_ cell_temp352 : 56|8@1+ (1,-40) [-40|215] "℃" Vector__XXX
 SG_ cell_temp351 : 48|8@1+ (1,-40) [-40|215] "℃" Vector__XXX
 SG_ cell_temp350 : 40|8@1+ (1,-40) [-40|215] "℃" Vector__XXX
 SG_ cell_temp349 : 32|8@1+ (1,-40) [-40|215] "℃" Vector__XXX
 SG_ cell_temp348 : 24|8@1+ (1,-40) [-40|215] "℃" Vector__XXX
 SG_ cell_temp347 : 16|8@1+ (1,-40) [-40|215] "℃" Vector__XXX
 SG_ cell_temp346 : 8|8@1+ (1,-40) [-40|215] "℃" Vector__XXX
 SG_ cell_temp345 : 0|8@1+ (1,-40) [-40|215] "℃" Vector__XXX

BO_ 2550202925 temp_msg45: 8 BMS
 SG_ cell_temp360 : 56|8@1+ (1,-40) [-40|215] "℃" Vector__XXX
 SG_ cell_temp359 : 48|8@1+ (1,-40) [-40|215] "℃" Vector__XXX
 SG_ cell_temp358 : 40|8@1+ (1,-40) [-40|215] "℃" Vector__XXX
 SG_ cell_temp357 : 32|8@1+ (1,-40) [-40|215] "℃" Vector__XXX
 SG_ cell_temp356 : 24|8@1+ (1,-40) [-40|215] "℃" Vector__XXX
 SG_ cell_temp355 : 16|8@1+ (1,-40) [-40|215] "℃" Vector__XXX
 SG_ cell_temp354 : 8|8@1+ (1,-40) [-40|215] "℃" Vector__XXX
 SG_ cell_temp353 : 0|8@1+ (1,-40) [-40|215] "℃" Vector__XXX

BO_ 2550202926 temp_msg46: 8 BMS
 SG_ cell_temp368 : 56|8@1+ (1,-40) [-40|215] "℃" Vector__XXX
 SG_ cell_temp367 : 48|8@1+ (1,-40) [-40|215] "℃" Vector__XXX
 SG_ cell_temp366 : 40|8@1+ (1,-40) [-40|215] "℃" Vector__XXX
 SG_ cell_temp365 : 32|8@1+ (1,-40) [-40|215] "℃" Vector__XXX
 SG_ cell_temp364 : 24|8@1+ (1,-40) [-40|215] "℃" Vector__XXX
 SG_ cell_temp363 : 16|8@1+ (1,-40) [-40|215] "℃" Vector__XXX
 SG_ cell_temp362 : 8|8@1+ (1,-40) [-40|215] "℃" Vector__XXX
 SG_ cell_temp361 : 0|8@1+ (1,-40) [-40|215] "℃" Vector__XXX

BO_ 2550202927 temp_msg47: 8 BMS
 SG_ cell_temp376 : 56|8@1+ (1,-40) [-40|215] "℃" Vector__XXX
 SG_ cell_temp375 : 48|8@1+ (1,-40) [-40|215] "℃" Vector__XXX
 SG_ cell_temp374 : 40|8@1+ (1,-40) [-40|215] "℃" Vector__XXX
 SG_ cell_temp373 : 32|8@1+ (1,-40) [-40|215] "℃" Vector__XXX
 SG_ cell_temp372 : 24|8@1+ (1,-40) [-40|215] "℃" Vector__XXX
 SG_ cell_temp371 : 16|8@1+ (1,-40) [-40|215] "℃" Vector__XXX
 SG_ cell_temp370 : 8|8@1+ (1,-40) [-40|215] "℃" Vector__XXX
 SG_ cell_temp369 : 0|8@1+ (1,-40) [-40|215] "℃" Vector__XXX

BO_ 2550202928 temp_msg48: 8 BMS
 SG_ cell_temp384 : 56|8@1+ (1,-40) [-40|215] "℃" Vector__XXX
 SG_ cell_temp383 : 48|8@1+ (1,-40) [-40|215] "℃" Vector__XXX
 SG_ cell_temp382 : 40|8@1+ (1,-40) [-40|215] "℃" Vector__XXX
 SG_ cell_temp381 : 32|8@1+ (1,-40) [-40|215] "℃" Vector__XXX
 SG_ cell_temp380 : 24|8@1+ (1,-40) [-40|215] "℃" Vector__XXX
 SG_ cell_temp379 : 16|8@1+ (1,-40) [-40|215] "℃" Vector__XXX
 SG_ cell_temp378 : 8|8@1+ (1,-40) [-40|215] "℃" Vector__XXX
 SG_ cell_temp377 : 0|8@1+ (1,-40) [-40|215] "℃" Vector__XXX

BO_ 2550202929 temp_msg49: 8 BMS
 SG_ cell_temp392 : 56|8@1+ (1,-40) [-40|215] "℃" Vector__XXX
 SG_ cell_temp391 : 48|8@1+ (1,-40) [-40|215] "℃" Vector__XXX
 SG_ cell_temp390 : 40|8@1+ (1,-40) [-40|215] "℃" Vector__XXX
 SG_ cell_temp389 : 32|8@1+ (1,-40) [-40|215] "℃" Vector__XXX
 SG_ cell_temp388 : 24|8@1+ (1,-40) [-40|215] "℃" Vector__XXX
 SG_ cell_temp387 : 16|8@1+ (1,-40) [-40|215] "℃" Vector__XXX
 SG_ cell_temp386 : 8|8@1+ (1,-40) [-40|215] "℃" Vector__XXX
 SG_ cell_temp385 : 0|8@1+ (1,-40) [-40|215] "℃" Vector__XXX

BO_ 2550202930 temp_msg50: 8 BMS
 SG_ cell_temp400 : 56|8@1+ (1,-40) [-40|215] "℃" Vector__XXX
 SG_ cell_temp399 : 48|8@1+ (1,-40) [-40|215] "℃" Vector__XXX
 SG_ cell_temp398 : 40|8@1+ (1,-40) [-40|215] "℃" Vector__XXX
 SG_ cell_temp397 : 32|8@1+ (1,-40) [-40|215] "℃" Vector__XXX
 SG_ cell_temp396 : 24|8@1+ (1,-40) [-40|215] "℃" Vector__XXX
 SG_ cell_temp395 : 16|8@1+ (1,-40) [-40|215] "℃" Vector__XXX
 SG_ cell_temp394 : 8|8@1+ (1,-40) [-40|215] "℃" Vector__XXX
 SG_ cell_temp393 : 0|8@1+ (1,-40) [-40|215] "℃" Vector__XXX

BO_ 2550202724 vol_msg100: 8 BMS
 SG_ cell_vol397 : 0|16@1+ (1,0) [0|65535] "mV" Vector__XXX
 SG_ cell_vol398 : 16|16@1+ (1,0) [0|65535] "mV" Vector__XXX
 SG_ cell_vol399 : 32|16@1+ (1,0) [0|65535] "mV" Vector__XXX
 SG_ cell_vol400 : 48|16@1+ (1,0) [0|65535] "mV" Vector__XXX

BO_ 2550202723 vol_msg099: 8 BMS
 SG_ cell_vol393 : 0|16@1+ (1,0) [0|65535] "mV" Vector__XXX
 SG_ cell_vol394 : 16|16@1+ (1,0) [0|65535] "mV" Vector__XXX
 SG_ cell_vol395 : 32|16@1+ (1,0) [0|65535] "mV" Vector__XXX
 SG_ cell_vol396 : 48|16@1+ (1,0) [0|65535] "mV" Vector__XXX

BO_ 2550202722 vol_msg098: 8 BMS
 SG_ cell_vol389 : 0|16@1+ (1,0) [0|65535] "mV" Vector__XXX
 SG_ cell_vol390 : 16|16@1+ (1,0) [0|65535] "mV" Vector__XXX
 SG_ cell_vol391 : 32|16@1+ (1,0) [0|65535] "mV" Vector__XXX
 SG_ cell_vol392 : 48|16@1+ (1,0) [0|65535] "mV" Vector__XXX

BO_ 2550202721 vol_msg097: 8 BMS
 SG_ cell_vol385 : 0|16@1+ (1,0) [0|65535] "mV" Vector__XXX
 SG_ cell_vol386 : 16|16@1+ (1,0) [0|65535] "mV" Vector__XXX
 SG_ cell_vol387 : 32|16@1+ (1,0) [0|65535] "mV" Vector__XXX
 SG_ cell_vol388 : 48|16@1+ (1,0) [0|65535] "mV" Vector__XXX

BO_ 2550202720 vol_msg096: 8 BMS
 SG_ cell_vol381 : 0|16@1+ (1,0) [0|65535] "mV" Vector__XXX
 SG_ cell_vol382 : 16|16@1+ (1,0) [0|65535] "mV" Vector__XXX
 SG_ cell_vol383 : 32|16@1+ (1,0) [0|65535] "mV" Vector__XXX
 SG_ cell_vol384 : 48|16@1+ (1,0) [0|65535] "mV" Vector__XXX

BO_ 2550202719 vol_msg095: 8 BMS
 SG_ cell_vol377 : 0|16@1+ (1,0) [0|65535] "mV" Vector__XXX
 SG_ cell_vol378 : 16|16@1+ (1,0) [0|65535] "mV" Vector__XXX
 SG_ cell_vol379 : 32|16@1+ (1,0) [0|65535] "mV" Vector__XXX
 SG_ cell_vol380 : 48|16@1+ (1,0) [0|65535] "mV" Vector__XXX

BO_ 2550202718 vol_msg094: 8 BMS
 SG_ cell_vol373 : 0|16@1+ (1,0) [0|65535] "mV" Vector__XXX
 SG_ cell_vol374 : 16|16@1+ (1,0) [0|65535] "mV" Vector__XXX
 SG_ cell_vol375 : 32|16@1+ (1,0) [0|65535] "mV" Vector__XXX
 SG_ cell_vol376 : 48|16@1+ (1,0) [0|65535] "mV" Vector__XXX

BO_ 2550202717 vol_msg093: 8 BMS
 SG_ cell_vol369 : 0|16@1+ (1,0) [0|65535] "mV" Vector__XXX
 SG_ cell_vol370 : 16|16@1+ (1,0) [0|65535] "mV" Vector__XXX
 SG_ cell_vol371 : 32|16@1+ (1,0) [0|65535] "mV" Vector__XXX
 SG_ cell_vol372 : 48|16@1+ (1,0) [0|65535] "mV" Vector__XXX

BO_ 2550202716 vol_msg092: 8 BMS
 SG_ cell_vol365 : 0|16@1+ (1,0) [0|65535] "mV" Vector__XXX
 SG_ cell_vol366 : 16|16@1+ (1,0) [0|65535] "mV" Vector__XXX
 SG_ cell_vol367 : 32|16@1+ (1,0) [0|65535] "mV" Vector__XXX
 SG_ cell_vol368 : 48|16@1+ (1,0) [0|65535] "mV" Vector__XXX

BO_ 2550202715 vol_msg091: 8 BMS
 SG_ cell_vol361 : 0|16@1+ (1,0) [0|65535] "mV" Vector__XXX
 SG_ cell_vol362 : 16|16@1+ (1,0) [0|65535] "mV" Vector__XXX
 SG_ cell_vol363 : 32|16@1+ (1,0) [0|65535] "mV" Vector__XXX
 SG_ cell_vol364 : 48|16@1+ (1,0) [0|65535] "mV" Vector__XXX

BO_ 2550202714 vol_msg090: 8 BMS
 SG_ cell_vol357 : 0|16@1+ (1,0) [0|65535] "mV" Vector__XXX
 SG_ cell_vol358 : 16|16@1+ (1,0) [0|65535] "mV" Vector__XXX
 SG_ cell_vol359 : 32|16@1+ (1,0) [0|65535] "mV" Vector__XXX
 SG_ cell_vol360 : 48|16@1+ (1,0) [0|65535] "mV" Vector__XXX

BO_ 2550202713 vol_msg089: 8 BMS
 SG_ cell_vol353 : 0|16@1+ (1,0) [0|65535] "mV" Vector__XXX
 SG_ cell_vol354 : 16|16@1+ (1,0) [0|65535] "mV" Vector__XXX
 SG_ cell_vol355 : 32|16@1+ (1,0) [0|65535] "mV" Vector__XXX
 SG_ cell_vol356 : 48|16@1+ (1,0) [0|65535] "mV" Vector__XXX

BO_ 2550202712 vol_msg088: 8 BMS
 SG_ cell_vol349 : 0|16@1+ (1,0) [0|65535] "mV" Vector__XXX
 SG_ cell_vol350 : 16|16@1+ (1,0) [0|65535] "mV" Vector__XXX
 SG_ cell_vol351 : 32|16@1+ (1,0) [0|65535] "mV" Vector__XXX
 SG_ cell_vol352 : 48|16@1+ (1,0) [0|65535] "mV" Vector__XXX

BO_ 2550202711 vol_msg087: 8 BMS
 SG_ cell_vol345 : 0|16@1+ (1,0) [0|65535] "mV" Vector__XXX
 SG_ cell_vol346 : 16|16@1+ (1,0) [0|65535] "mV" Vector__XXX
 SG_ cell_vol347 : 32|16@1+ (1,0) [0|65535] "mV" Vector__XXX
 SG_ cell_vol348 : 48|16@1+ (1,0) [0|65535] "mV" Vector__XXX

BO_ 2550202710 vol_msg086: 8 BMS
 SG_ cell_vol341 : 0|16@1+ (1,0) [0|65535] "mV" Vector__XXX
 SG_ cell_vol342 : 16|16@1+ (1,0) [0|65535] "mV" Vector__XXX
 SG_ cell_vol343 : 32|16@1+ (1,0) [0|65535] "mV" Vector__XXX
 SG_ cell_vol344 : 48|16@1+ (1,0) [0|65535] "mV" Vector__XXX

BO_ 2550202709 vol_msg085: 8 BMS
 SG_ cell_vol337 : 0|16@1+ (1,0) [0|65535] "mV" Vector__XXX
 SG_ cell_vol338 : 16|16@1+ (1,0) [0|65535] "mV" Vector__XXX
 SG_ cell_vol339 : 32|16@1+ (1,0) [0|65535] "mV" Vector__XXX
 SG_ cell_vol340 : 48|16@1+ (1,0) [0|65535] "mV" Vector__XXX

BO_ 2550202708 vol_msg084: 8 BMS
 SG_ cell_vol333 : 0|16@1+ (1,0) [0|65535] "mV" Vector__XXX
 SG_ cell_vol334 : 16|16@1+ (1,0) [0|65535] "mV" Vector__XXX
 SG_ cell_vol335 : 32|16@1+ (1,0) [0|65535] "mV" Vector__XXX
 SG_ cell_vol336 : 48|16@1+ (1,0) [0|65535] "mV" Vector__XXX

BO_ 2550202707 vol_msg083: 8 BMS
 SG_ cell_vol329 : 0|16@1+ (1,0) [0|65535] "mV" Vector__XXX
 SG_ cell_vol330 : 16|16@1+ (1,0) [0|65535] "mV" Vector__XXX
 SG_ cell_vol331 : 32|16@1+ (1,0) [0|65535] "mV" Vector__XXX
 SG_ cell_vol332 : 48|16@1+ (1,0) [0|65535] "mV" Vector__XXX

BO_ 2550202706 vol_msg082: 8 BMS
 SG_ cell_vol325 : 0|16@1+ (1,0) [0|65535] "mV" Vector__XXX
 SG_ cell_vol326 : 16|16@1+ (1,0) [0|65535] "mV" Vector__XXX
 SG_ cell_vol327 : 32|16@1+ (1,0) [0|65535] "mV" Vector__XXX
 SG_ cell_vol328 : 48|16@1+ (1,0) [0|65535] "mV" Vector__XXX

BO_ 2550202705 vol_msg081: 8 BMS
 SG_ cell_vol321 : 0|16@1+ (1,0) [0|65535] "mV" Vector__XXX
 SG_ cell_vol322 : 16|16@1+ (1,0) [0|65535] "mV" Vector__XXX
 SG_ cell_vol323 : 32|16@1+ (1,0) [0|65535] "mV" Vector__XXX
 SG_ cell_vol324 : 48|16@1+ (1,0) [0|65535] "mV" Vector__XXX

BO_ 2550202704 vol_msg080: 8 BMS
 SG_ cell_vol317 : 0|16@1+ (1,0) [0|65535] "mV" Vector__XXX
 SG_ cell_vol318 : 16|16@1+ (1,0) [0|65535] "mV" Vector__XXX
 SG_ cell_vol319 : 32|16@1+ (1,0) [0|65535] "mV" Vector__XXX
 SG_ cell_vol320 : 48|16@1+ (1,0) [0|65535] "mV" Vector__XXX

BO_ 2550202703 vol_msg079: 8 BMS
 SG_ cell_vol313 : 0|16@1+ (1,0) [0|65535] "mV" Vector__XXX
 SG_ cell_vol314 : 16|16@1+ (1,0) [0|65535] "mV" Vector__XXX
 SG_ cell_vol315 : 32|16@1+ (1,0) [0|65535] "mV" Vector__XXX
 SG_ cell_vol316 : 48|16@1+ (1,0) [0|65535] "mV" Vector__XXX

BO_ 2550202702 vol_msg078: 8 BMS
 SG_ cell_vol309 : 0|16@1+ (1,0) [0|65535] "mV" Vector__XXX
 SG_ cell_vol310 : 16|16@1+ (1,0) [0|65535] "mV" Vector__XXX
 SG_ cell_vol311 : 32|16@1+ (1,0) [0|65535] "mV" Vector__XXX
 SG_ cell_vol312 : 48|16@1+ (1,0) [0|65535] "mV" Vector__XXX

BO_ 2550202701 vol_msg077: 8 BMS
 SG_ cell_vol305 : 0|16@1+ (1,0) [0|65535] "mV" Vector__XXX
 SG_ cell_vol306 : 16|16@1+ (1,0) [0|65535] "mV" Vector__XXX
 SG_ cell_vol307 : 32|16@1+ (1,0) [0|65535] "mV" Vector__XXX
 SG_ cell_vol308 : 48|16@1+ (1,0) [0|65535] "mV" Vector__XXX

BO_ 2550202700 vol_msg076: 8 BMS
 SG_ cell_vol301 : 0|16@1+ (1,0) [0|65535] "mV" Vector__XXX
 SG_ cell_vol302 : 16|16@1+ (1,0) [0|65535] "mV" Vector__XXX
 SG_ cell_vol303 : 32|16@1+ (1,0) [0|65535] "mV" Vector__XXX
 SG_ cell_vol304 : 48|16@1+ (1,0) [0|65535] "mV" Vector__XXX

BO_ 2550202699 vol_msg075: 8 BMS
 SG_ cell_vol297 : 0|16@1+ (1,0) [0|65535] "mV" Vector__XXX
 SG_ cell_vol298 : 16|16@1+ (1,0) [0|65535] "mV" Vector__XXX
 SG_ cell_vol299 : 32|16@1+ (1,0) [0|65535] "mV" Vector__XXX
 SG_ cell_vol300 : 48|16@1+ (1,0) [0|65535] "mV" Vector__XXX

BO_ 2550202698 vol_msg074: 8 BMS
 SG_ cell_vol293 : 0|16@1+ (1,0) [0|65535] "mV" Vector__XXX
 SG_ cell_vol294 : 16|16@1+ (1,0) [0|65535] "mV" Vector__XXX
 SG_ cell_vol295 : 32|16@1+ (1,0) [0|65535] "mV" Vector__XXX
 SG_ cell_vol296 : 48|16@1+ (1,0) [0|65535] "mV" Vector__XXX

BO_ 2550202697 vol_msg073: 8 BMS
 SG_ cell_vol289 : 0|16@1+ (1,0) [0|65535] "mV" Vector__XXX
 SG_ cell_vol290 : 16|16@1+ (1,0) [0|65535] "mV" Vector__XXX
 SG_ cell_vol291 : 32|16@1+ (1,0) [0|65535] "mV" Vector__XXX
 SG_ cell_vol292 : 48|16@1+ (1,0) [0|65535] "mV" Vector__XXX

BO_ 2550202696 vol_msg072: 8 BMS
 SG_ cell_vol285 : 0|16@1+ (1,0) [0|65535] "mV" Vector__XXX
 SG_ cell_vol286 : 16|16@1+ (1,0) [0|65535] "mV" Vector__XXX
 SG_ cell_vol287 : 32|16@1+ (1,0) [0|65535] "mV" Vector__XXX
 SG_ cell_vol288 : 48|16@1+ (1,0) [0|65535] "mV" Vector__XXX

BO_ 2550202695 vol_msg071: 8 BMS
 SG_ cell_vol281 : 0|16@1+ (1,0) [0|65535] "mV" Vector__XXX
 SG_ cell_vol282 : 16|16@1+ (1,0) [0|65535] "mV" Vector__XXX
 SG_ cell_vol283 : 32|16@1+ (1,0) [0|65535] "mV" Vector__XXX
 SG_ cell_vol284 : 48|16@1+ (1,0) [0|65535] "mV" Vector__XXX

BO_ 2550202694 vol_msg070: 8 BMS
 SG_ cell_vol277 : 0|16@1+ (1,0) [0|65535] "mV" Vector__XXX
 SG_ cell_vol278 : 16|16@1+ (1,0) [0|65535] "mV" Vector__XXX
 SG_ cell_vol279 : 32|16@1+ (1,0) [0|65535] "mV" Vector__XXX
 SG_ cell_vol280 : 48|16@1+ (1,0) [0|65535] "mV" Vector__XXX

BO_ 2550202693 vol_msg069: 8 BMS
 SG_ cell_vol273 : 0|16@1+ (1,0) [0|65535] "mV" Vector__XXX
 SG_ cell_vol274 : 16|16@1+ (1,0) [0|65535] "mV" Vector__XXX
 SG_ cell_vol275 : 32|16@1+ (1,0) [0|65535] "mV" Vector__XXX
 SG_ cell_vol276 : 48|16@1+ (1,0) [0|65535] "mV" Vector__XXX

BO_ 2550202692 vol_msg068: 8 BMS
 SG_ cell_vol269 : 0|16@1+ (1,0) [0|65535] "mV" Vector__XXX
 SG_ cell_vol270 : 16|16@1+ (1,0) [0|65535] "mV" Vector__XXX
 SG_ cell_vol271 : 32|16@1+ (1,0) [0|65535] "mV" Vector__XXX
 SG_ cell_vol272 : 48|16@1+ (1,0) [0|65535] "mV" Vector__XXX

BO_ 2550202691 vol_msg067: 8 BMS
 SG_ cell_vol265 : 0|16@1+ (1,0) [0|65535] "mV" Vector__XXX
 SG_ cell_vol266 : 16|16@1+ (1,0) [0|65535] "mV" Vector__XXX
 SG_ cell_vol267 : 32|16@1+ (1,0) [0|65535] "mV" Vector__XXX
 SG_ cell_vol268 : 48|16@1+ (1,0) [0|65535] "mV" Vector__XXX

BO_ 2550202690 vol_msg066: 8 BMS
 SG_ cell_vol261 : 0|16@1+ (1,0) [0|65535] "mV" Vector__XXX
 SG_ cell_vol262 : 16|16@1+ (1,0) [0|65535] "mV" Vector__XXX
 SG_ cell_vol263 : 32|16@1+ (1,0) [0|65535] "mV" Vector__XXX
 SG_ cell_vol264 : 48|16@1+ (1,0) [0|65535] "mV" Vector__XXX

BO_ 2550202689 vol_msg065: 8 BMS
 SG_ cell_vol257 : 0|16@1+ (1,0) [0|65535] "mV" Vector__XXX
 SG_ cell_vol258 : 16|16@1+ (1,0) [0|65535] "mV" Vector__XXX
 SG_ cell_vol259 : 32|16@1+ (1,0) [0|65535] "mV" Vector__XXX
 SG_ cell_vol260 : 48|16@1+ (1,0) [0|65535] "mV" Vector__XXX

BO_ 2550202688 vol_msg064: 8 BMS
 SG_ cell_vol253 : 0|16@1+ (1,0) [0|65535] "mV" Vector__XXX
 SG_ cell_vol254 : 16|16@1+ (1,0) [0|65535] "mV" Vector__XXX
 SG_ cell_vol255 : 32|16@1+ (1,0) [0|65535] "mV" Vector__XXX
 SG_ cell_vol256 : 48|16@1+ (1,0) [0|65535] "mV" Vector__XXX

BO_ 2550202687 vol_msg063: 8 BMS
 SG_ cell_vol249 : 0|16@1+ (1,0) [0|65535] "mV" Vector__XXX
 SG_ cell_vol250 : 16|16@1+ (1,0) [0|65535] "mV" Vector__XXX
 SG_ cell_vol251 : 32|16@1+ (1,0) [0|65535] "mV" Vector__XXX
 SG_ cell_vol252 : 48|16@1+ (1,0) [0|65535] "mV" Vector__XXX

BO_ 2550202686 vol_msg062: 8 BMS
 SG_ cell_vol245 : 0|16@1+ (1,0) [0|65535] "mV" Vector__XXX
 SG_ cell_vol246 : 16|16@1+ (1,0) [0|65535] "mV" Vector__XXX
 SG_ cell_vol247 : 32|16@1+ (1,0) [0|65535] "mV" Vector__XXX
 SG_ cell_vol248 : 48|16@1+ (1,0) [0|65535] "mV" Vector__XXX

BO_ 2550202685 vol_msg061: 8 BMS
 SG_ cell_vol241 : 0|16@1+ (1,0) [0|65535] "mV" Vector__XXX
 SG_ cell_vol242 : 16|16@1+ (1,0) [0|65535] "mV" Vector__XXX
 SG_ cell_vol243 : 32|16@1+ (1,0) [0|65535] "mV" Vector__XXX
 SG_ cell_vol244 : 48|16@1+ (1,0) [0|65535] "mV" Vector__XXX

BO_ 2550202684 vol_msg060: 8 BMS
 SG_ cell_vol237 : 0|16@1+ (1,0) [0|65535] "mV" Vector__XXX
 SG_ cell_vol238 : 16|16@1+ (1,0) [0|65535] "mV" Vector__XXX
 SG_ cell_vol239 : 32|16@1+ (1,0) [0|65535] "mV" Vector__XXX
 SG_ cell_vol240 : 48|16@1+ (1,0) [0|65535] "mV" Vector__XXX

BO_ 2550202683 vol_msg059: 8 BMS
 SG_ cell_vol233 : 0|16@1+ (1,0) [0|65535] "mV" Vector__XXX
 SG_ cell_vol234 : 16|16@1+ (1,0) [0|65535] "mV" Vector__XXX
 SG_ cell_vol235 : 32|16@1+ (1,0) [0|65535] "mV" Vector__XXX
 SG_ cell_vol236 : 48|16@1+ (1,0) [0|65535] "mV" Vector__XXX

BO_ 2550202682 vol_msg058: 8 BMS
 SG_ cell_vol229 : 0|16@1+ (1,0) [0|65535] "mV" Vector__XXX
 SG_ cell_vol230 : 16|16@1+ (1,0) [0|65535] "mV" Vector__XXX
 SG_ cell_vol231 : 32|16@1+ (1,0) [0|65535] "mV" Vector__XXX
 SG_ cell_vol232 : 48|16@1+ (1,0) [0|65535] "mV" Vector__XXX

BO_ 2550202681 vol_msg057: 8 BMS
 SG_ cell_vol225 : 0|16@1+ (1,0) [0|65535] "mV" Vector__XXX
 SG_ cell_vol226 : 16|16@1+ (1,0) [0|65535] "mV" Vector__XXX
 SG_ cell_vol227 : 32|16@1+ (1,0) [0|65535] "mV" Vector__XXX
 SG_ cell_vol228 : 48|16@1+ (1,0) [0|65535] "mV" Vector__XXX

BO_ 2550202680 vol_msg056: 8 BMS
 SG_ cell_vol221 : 0|16@1+ (1,0) [0|65535] "mV" Vector__XXX
 SG_ cell_vol222 : 16|16@1+ (1,0) [0|65535] "mV" Vector__XXX
 SG_ cell_vol223 : 32|16@1+ (1,0) [0|65535] "mV" Vector__XXX
 SG_ cell_vol224 : 48|16@1+ (1,0) [0|65535] "mV" Vector__XXX

BO_ 2550202679 vol_msg055: 8 BMS
 SG_ cell_vol217 : 0|16@1+ (1,0) [0|65535] "mV" Vector__XXX
 SG_ cell_vol218 : 16|16@1+ (1,0) [0|65535] "mV" Vector__XXX
 SG_ cell_vol219 : 32|16@1+ (1,0) [0|65535] "mV" Vector__XXX
 SG_ cell_vol220 : 48|16@1+ (1,0) [0|65535] "mV" Vector__XXX

BO_ 2550202678 vol_msg054: 8 BMS
 SG_ cell_vol213 : 0|16@1+ (1,0) [0|65535] "mV" Vector__XXX
 SG_ cell_vol214 : 16|16@1+ (1,0) [0|65535] "mV" Vector__XXX
 SG_ cell_vol215 : 32|16@1+ (1,0) [0|65535] "mV" Vector__XXX
 SG_ cell_vol216 : 48|16@1+ (1,0) [0|65535] "mV" Vector__XXX

BO_ 2550202677 vol_msg053: 8 BMS
 SG_ cell_vol209 : 0|16@1+ (1,0) [0|65535] "mV" Vector__XXX
 SG_ cell_vol210 : 16|16@1+ (1,0) [0|65535] "mV" Vector__XXX
 SG_ cell_vol211 : 32|16@1+ (1,0) [0|65535] "mV" Vector__XXX
 SG_ cell_vol212 : 48|16@1+ (1,0) [0|65535] "mV" Vector__XXX

BO_ 2550202676 vol_msg052: 8 BMS
 SG_ cell_vol205 : 0|16@1+ (1,0) [0|65535] "mV" Vector__XXX
 SG_ cell_vol206 : 16|16@1+ (1,0) [0|65535] "mV" Vector__XXX
 SG_ cell_vol207 : 32|16@1+ (1,0) [0|65535] "mV" Vector__XXX
 SG_ cell_vol208 : 48|16@1+ (1,0) [0|65535] "mV" Vector__XXX

BO_ 2550202675 vol_msg051: 8 BMS
 SG_ cell_vol201 : 0|16@1+ (1,0) [0|65535] "mV" Vector__XXX
 SG_ cell_vol202 : 16|16@1+ (1,0) [0|65535] "mV" Vector__XXX
 SG_ cell_vol203 : 32|16@1+ (1,0) [0|65535] "mV" Vector__XXX
 SG_ cell_vol204 : 48|16@1+ (1,0) [0|65535] "mV" Vector__XXX

BO_ 2550202674 vol_msg050: 8 BMS
 SG_ cell_vol197 : 0|16@1+ (1,0) [0|65535] "mV" Vector__XXX
 SG_ cell_vol198 : 16|16@1+ (1,0) [0|65535] "mV" Vector__XXX
 SG_ cell_vol199 : 32|16@1+ (1,0) [0|65535] "mV" Vector__XXX
 SG_ cell_vol200 : 48|16@1+ (1,0) [0|65535] "mV" Vector__XXX

BO_ 2550202673 vol_msg049: 8 BMS
 SG_ cell_vol193 : 0|16@1+ (1,0) [0|65535] "mV" Vector__XXX
 SG_ cell_vol194 : 16|16@1+ (1,0) [0|65535] "mV" Vector__XXX
 SG_ cell_vol195 : 32|16@1+ (1,0) [0|65535] "mV" Vector__XXX
 SG_ cell_vol196 : 48|16@1+ (1,0) [0|65535] "mV" Vector__XXX

BO_ 2550202672 vol_msg048: 8 BMS
 SG_ cell_vol189 : 0|16@1+ (1,0) [0|65535] "mV" Vector__XXX
 SG_ cell_vol190 : 16|16@1+ (1,0) [0|65535] "mV" Vector__XXX
 SG_ cell_vol191 : 32|16@1+ (1,0) [0|65535] "mV" Vector__XXX
 SG_ cell_vol192 : 48|16@1+ (1,0) [0|65535] "mV" Vector__XXX

BO_ 2550202671 vol_msg047: 8 BMS
 SG_ cell_vol185 : 0|16@1+ (1,0) [0|65535] "mV" Vector__XXX
 SG_ cell_vol186 : 16|16@1+ (1,0) [0|65535] "mV" Vector__XXX
 SG_ cell_vol187 : 32|16@1+ (1,0) [0|65535] "mV" Vector__XXX
 SG_ cell_vol188 : 48|16@1+ (1,0) [0|65535] "mV" Vector__XXX

BO_ 2550202670 vol_msg046: 8 BMS
 SG_ cell_vol181 : 0|16@1+ (1,0) [0|65535] "mV" Vector__XXX
 SG_ cell_vol182 : 16|16@1+ (1,0) [0|65535] "mV" Vector__XXX
 SG_ cell_vol183 : 32|16@1+ (1,0) [0|65535] "mV" Vector__XXX
 SG_ cell_vol184 : 48|16@1+ (1,0) [0|65535] "mV" Vector__XXX

BO_ 2550202669 vol_msg045: 8 BMS
 SG_ cell_vol177 : 0|16@1+ (1,0) [0|65535] "mV" Vector__XXX
 SG_ cell_vol178 : 16|16@1+ (1,0) [0|65535] "mV" Vector__XXX
 SG_ cell_vol179 : 32|16@1+ (1,0) [0|65535] "mV" Vector__XXX
 SG_ cell_vol180 : 48|16@1+ (1,0) [0|65535] "mV" Vector__XXX

BO_ 2550202668 vol_msg044: 8 BMS
 SG_ cell_vol173 : 0|16@1+ (1,0) [0|65535] "mV" Vector__XXX
 SG_ cell_vol174 : 16|16@1+ (1,0) [0|65535] "mV" Vector__XXX
 SG_ cell_vol175 : 32|16@1+ (1,0) [0|65535] "mV" Vector__XXX
 SG_ cell_vol176 : 48|16@1+ (1,0) [0|65535] "mV" Vector__XXX

BO_ 2550202667 vol_msg043: 8 BMS
 SG_ cell_vol169 : 0|16@1+ (1,0) [0|65535] "mV" Vector__XXX
 SG_ cell_vol170 : 16|16@1+ (1,0) [0|65535] "mV" Vector__XXX
 SG_ cell_vol171 : 32|16@1+ (1,0) [0|65535] "mV" Vector__XXX
 SG_ cell_vol172 : 48|16@1+ (1,0) [0|65535] "mV" Vector__XXX

BO_ 2550202666 vol_msg042: 8 BMS
 SG_ cell_vol165 : 0|16@1+ (1,0) [0|65535] "mV" Vector__XXX
 SG_ cell_vol166 : 16|16@1+ (1,0) [0|65535] "mV" Vector__XXX
 SG_ cell_vol167 : 32|16@1+ (1,0) [0|65535] "mV" Vector__XXX
 SG_ cell_vol168 : 48|16@1+ (1,0) [0|65535] "mV" Vector__XXX

BO_ 2550202665 vol_msg041: 8 BMS
 SG_ cell_vol161 : 0|16@1+ (1,0) [0|65535] "mV" Vector__XXX
 SG_ cell_vol162 : 16|16@1+ (1,0) [0|65535] "mV" Vector__XXX
 SG_ cell_vol163 : 32|16@1+ (1,0) [0|65535] "mV" Vector__XXX
 SG_ cell_vol164 : 48|16@1+ (1,0) [0|65535] "mV" Vector__XXX

BO_ 2550202664 vol_msg040: 8 BMS
 SG_ cell_vol157 : 0|16@1+ (1,0) [0|65535] "mV" Vector__XXX
 SG_ cell_vol158 : 16|16@1+ (1,0) [0|65535] "mV" Vector__XXX
 SG_ cell_vol159 : 32|16@1+ (1,0) [0|65535] "mV" Vector__XXX
 SG_ cell_vol160 : 48|16@1+ (1,0) [0|65535] "mV" Vector__XXX

BO_ 2550202663 vol_msg039: 8 BMS
 SG_ cell_vol153 : 0|16@1+ (1,0) [0|65535] "mV" Vector__XXX
 SG_ cell_vol154 : 16|16@1+ (1,0) [0|65535] "mV" Vector__XXX
 SG_ cell_vol155 : 32|16@1+ (1,0) [0|65535] "mV" Vector__XXX
 SG_ cell_vol156 : 48|16@1+ (1,0) [0|65535] "mV" Vector__XXX

BO_ 2550202662 vol_msg038: 8 BMS
 SG_ cell_vol149 : 0|16@1+ (1,0) [0|65535] "mV" Vector__XXX
 SG_ cell_vol150 : 16|16@1+ (1,0) [0|65535] "mV" Vector__XXX
 SG_ cell_vol151 : 32|16@1+ (1,0) [0|65535] "mV" Vector__XXX
 SG_ cell_vol152 : 48|16@1+ (1,0) [0|65535] "mV" Vector__XXX

BO_ 2550202661 vol_msg037: 8 BMS
 SG_ cell_vol145 : 0|16@1+ (1,0) [0|65535] "mV" Vector__XXX
 SG_ cell_vol146 : 16|16@1+ (1,0) [0|65535] "mV" Vector__XXX
 SG_ cell_vol147 : 32|16@1+ (1,0) [0|65535] "mV" Vector__XXX
 SG_ cell_vol148 : 48|16@1+ (1,0) [0|65535] "mV" Vector__XXX

BO_ 2550202660 vol_msg036: 8 BMS
 SG_ cell_vol141 : 0|16@1+ (1,0) [0|65535] "mV" Vector__XXX
 SG_ cell_vol142 : 16|16@1+ (1,0) [0|65535] "mV" Vector__XXX
 SG_ cell_vol143 : 32|16@1+ (1,0) [0|65535] "mV" Vector__XXX
 SG_ cell_vol144 : 48|16@1+ (1,0) [0|65535] "mV" Vector__XXX

BO_ 2550202659 vol_msg035: 8 BMS
 SG_ cell_vol137 : 0|16@1+ (1,0) [0|65535] "mV" Vector__XXX
 SG_ cell_vol138 : 16|16@1+ (1,0) [0|65535] "mV" Vector__XXX
 SG_ cell_vol139 : 32|16@1+ (1,0) [0|65535] "mV" Vector__XXX
 SG_ cell_vol140 : 48|16@1+ (1,0) [0|65535] "mV" Vector__XXX

BO_ 2550202658 vol_msg034: 8 BMS
 SG_ cell_vol133 : 0|16@1+ (1,0) [0|65535] "mV" Vector__XXX
 SG_ cell_vol134 : 16|16@1+ (1,0) [0|65535] "mV" Vector__XXX
 SG_ cell_vol135 : 32|16@1+ (1,0) [0|65535] "mV" Vector__XXX
 SG_ cell_vol136 : 48|16@1+ (1,0) [0|65535] "mV" Vector__XXX

BO_ 2550202657 vol_msg033: 8 BMS
 SG_ cell_vol129 : 0|16@1+ (1,0) [0|65535] "mV" Vector__XXX
 SG_ cell_vol130 : 16|16@1+ (1,0) [0|65535] "mV" Vector__XXX
 SG_ cell_vol131 : 32|16@1+ (1,0) [0|65535] "mV" Vector__XXX
 SG_ cell_vol132 : 48|16@1+ (1,0) [0|65535] "mV" Vector__XXX

BO_ 2550202656 vol_msg032: 8 BMS
 SG_ cell_vol125 : 0|16@1+ (1,0) [0|65535] "mV" Vector__XXX
 SG_ cell_vol126 : 16|16@1+ (1,0) [0|65535] "mV" Vector__XXX
 SG_ cell_vol127 : 32|16@1+ (1,0) [0|65535] "mV" Vector__XXX
 SG_ cell_vol128 : 48|16@1+ (1,0) [0|65535] "mV" Vector__XXX

BO_ 2550202655 vol_msg031: 8 BMS
 SG_ cell_vol121 : 0|16@1+ (1,0) [0|65535] "mV" Vector__XXX
 SG_ cell_vol122 : 16|16@1+ (1,0) [0|65535] "mV" Vector__XXX
 SG_ cell_vol123 : 32|16@1+ (1,0) [0|65535] "mV" Vector__XXX
 SG_ cell_vol124 : 48|16@1+ (1,0) [0|65535] "mV" Vector__XXX

BO_ 2550202654 vol_msg030: 8 BMS
 SG_ cell_vol117 : 0|16@1+ (1,0) [0|65535] "mV" Vector__XXX
 SG_ cell_vol118 : 16|16@1+ (1,0) [0|65535] "mV" Vector__XXX
 SG_ cell_vol119 : 32|16@1+ (1,0) [0|65535] "mV" Vector__XXX
 SG_ cell_vol120 : 48|16@1+ (1,0) [0|65535] "mV" Vector__XXX

BO_ 2550202653 vol_msg029: 8 BMS
 SG_ cell_vol113 : 0|16@1+ (1,0) [0|65535] "mV" Vector__XXX
 SG_ cell_vol114 : 16|16@1+ (1,0) [0|65535] "mV" Vector__XXX
 SG_ cell_vol115 : 32|16@1+ (1,0) [0|65535] "mV" Vector__XXX
 SG_ cell_vol116 : 48|16@1+ (1,0) [0|65535] "mV" Vector__XXX

BO_ 2550202652 vol_msg028: 8 BMS
 SG_ cell_vol109 : 0|16@1+ (1,0) [0|65535] "mV" Vector__XXX
 SG_ cell_vol110 : 16|16@1+ (1,0) [0|65535] "mV" Vector__XXX
 SG_ cell_vol111 : 32|16@1+ (1,0) [0|65535] "mV" Vector__XXX
 SG_ cell_vol112 : 48|16@1+ (1,0) [0|65535] "mV" Vector__XXX

BO_ 2550202651 vol_msg027: 8 BMS
 SG_ cell_vol105 : 0|16@1+ (1,0) [0|65535] "mV" Vector__XXX
 SG_ cell_vol106 : 16|16@1+ (1,0) [0|65535] "mV" Vector__XXX
 SG_ cell_vol107 : 32|16@1+ (1,0) [0|65535] "mV" Vector__XXX
 SG_ cell_vol108 : 48|16@1+ (1,0) [0|65535] "mV" Vector__XXX

BO_ 2550202650 vol_msg026: 8 BMS
 SG_ cell_vol101 : 0|16@1+ (1,0) [0|65535] "mV" Vector__XXX
 SG_ cell_vol102 : 16|16@1+ (1,0) [0|65535] "mV" Vector__XXX
 SG_ cell_vol103 : 32|16@1+ (1,0) [0|65535] "mV" Vector__XXX
 SG_ cell_vol104 : 48|16@1+ (1,0) [0|65535] "mV" Vector__XXX

BO_ 2550202649 vol_msg025: 8 BMS
 SG_ cell_vol97 : 0|16@1+ (1,0) [0|65535] "mV" Vector__XXX
 SG_ cell_vol98 : 16|16@1+ (1,0) [0|65535] "mV" Vector__XXX
 SG_ cell_vol99 : 32|16@1+ (1,0) [0|65535] "mV" Vector__XXX
 SG_ cell_vol100 : 48|16@1+ (1,0) [0|65535] "mV" Vector__XXX

BO_ 2550202648 vol_msg024: 8 BMS
 SG_ cell_vol93 : 0|16@1+ (1,0) [0|65535] "mV" Vector__XXX
 SG_ cell_vol94 : 16|16@1+ (1,0) [0|65535] "mV" Vector__XXX
 SG_ cell_vol95 : 32|16@1+ (1,0) [0|65535] "mV" Vector__XXX
 SG_ cell_vol96 : 48|16@1+ (1,0) [0|65535] "mV" Vector__XXX

BO_ 2550202647 vol_msg023: 8 BMS
 SG_ cell_vol89 : 0|16@1+ (1,0) [0|65535] "mV" Vector__XXX
 SG_ cell_vol90 : 16|16@1+ (1,0) [0|65535] "mV" Vector__XXX
 SG_ cell_vol91 : 32|16@1+ (1,0) [0|65535] "mV" Vector__XXX
 SG_ cell_vol92 : 48|16@1+ (1,0) [0|65535] "mV" Vector__XXX

BO_ 2550202646 vol_msg022: 8 BMS
 SG_ cell_vol85 : 0|16@1+ (1,0) [0|65535] "mV" Vector__XXX
 SG_ cell_vol86 : 16|16@1+ (1,0) [0|65535] "mV" Vector__XXX
 SG_ cell_vol87 : 32|16@1+ (1,0) [0|65535] "mV" Vector__XXX
 SG_ cell_vol88 : 48|16@1+ (1,0) [0|65535] "mV" Vector__XXX

BO_ 2550202645 vol_msg021: 8 BMS
 SG_ cell_vol81 : 0|16@1+ (1,0) [0|65535] "mV" Vector__XXX
 SG_ cell_vol82 : 16|16@1+ (1,0) [0|65535] "mV" Vector__XXX
 SG_ cell_vol83 : 32|16@1+ (1,0) [0|65535] "mV" Vector__XXX
 SG_ cell_vol84 : 48|16@1+ (1,0) [0|65535] "mV" Vector__XXX

BO_ 2550202644 vol_msg020: 8 BMS
 SG_ cell_vol77 : 0|16@1+ (1,0) [0|65535] "mV" Vector__XXX
 SG_ cell_vol78 : 16|16@1+ (1,0) [0|65535] "mV" Vector__XXX
 SG_ cell_vol79 : 32|16@1+ (1,0) [0|65535] "mV" Vector__XXX
 SG_ cell_vol80 : 48|16@1+ (1,0) [0|65535] "mV" Vector__XXX

BO_ 2550202643 vol_msg019: 8 BMS
 SG_ cell_vol73 : 0|16@1+ (1,0) [0|65535] "mV" Vector__XXX
 SG_ cell_vol74 : 16|16@1+ (1,0) [0|65535] "mV" Vector__XXX
 SG_ cell_vol75 : 32|16@1+ (1,0) [0|65535] "mV" Vector__XXX
 SG_ cell_vol76 : 48|16@1+ (1,0) [0|65535] "mV" Vector__XXX

BO_ 2550202642 vol_msg018: 8 BMS
 SG_ cell_vol69 : 0|16@1+ (1,0) [0|65535] "mV" Vector__XXX
 SG_ cell_vol70 : 16|16@1+ (1,0) [0|65535] "mV" Vector__XXX
 SG_ cell_vol71 : 32|16@1+ (1,0) [0|65535] "mV" Vector__XXX
 SG_ cell_vol72 : 48|16@1+ (1,0) [0|65535] "mV" Vector__XXX

BO_ 2550202641 vol_msg017: 8 BMS
 SG_ cell_vol65 : 0|16@1+ (1,0) [0|65535] "mV" Vector__XXX
 SG_ cell_vol66 : 16|16@1+ (1,0) [0|65535] "mV" Vector__XXX
 SG_ cell_vol67 : 32|16@1+ (1,0) [0|65535] "mV" Vector__XXX
 SG_ cell_vol68 : 48|16@1+ (1,0) [0|65535] "mV" Vector__XXX

BO_ 2550202640 vol_msg016: 8 BMS
 SG_ cell_vol61 : 0|16@1+ (1,0) [0|65535] "mV" Vector__XXX
 SG_ cell_vol62 : 16|16@1+ (1,0) [0|65535] "mV" Vector__XXX
 SG_ cell_vol63 : 32|16@1+ (1,0) [0|65535] "mV" Vector__XXX
 SG_ cell_vol64 : 48|16@1+ (1,0) [0|65535] "mV" Vector__XXX

BO_ 2550202639 vol_msg015: 8 BMS
 SG_ cell_vol57 : 0|16@1+ (1,0) [0|65535] "mV" Vector__XXX
 SG_ cell_vol58 : 16|16@1+ (1,0) [0|65535] "mV" Vector__XXX
 SG_ cell_vol59 : 32|16@1+ (1,0) [0|65535] "mV" Vector__XXX
 SG_ cell_vol60 : 48|16@1+ (1,0) [0|65535] "mV" Vector__XXX

BO_ 2550202638 vol_msg014: 8 BMS
 SG_ cell_vol53 : 0|16@1+ (1,0) [0|65535] "mV" Vector__XXX
 SG_ cell_vol54 : 16|16@1+ (1,0) [0|65535] "mV" Vector__XXX
 SG_ cell_vol55 : 32|16@1+ (1,0) [0|65535] "mV" Vector__XXX
 SG_ cell_vol56 : 48|16@1+ (1,0) [0|65535] "mV" Vector__XXX

BO_ 2550202637 vol_msg013: 8 BMS
 SG_ cell_vol49 : 0|16@1+ (1,0) [0|65535] "mV" Vector__XXX
 SG_ cell_vol50 : 16|16@1+ (1,0) [0|65535] "mV" Vector__XXX
 SG_ cell_vol51 : 32|16@1+ (1,0) [0|65535] "mV" Vector__XXX
 SG_ cell_vol52 : 48|16@1+ (1,0) [0|65535] "mV" Vector__XXX

BO_ 2550202636 vol_msg012: 8 BMS
 SG_ cell_vol45 : 0|16@1+ (1,0) [0|65535] "mV" Vector__XXX
 SG_ cell_vol46 : 16|16@1+ (1,0) [0|65535] "mV" Vector__XXX
 SG_ cell_vol47 : 32|16@1+ (1,0) [0|65535] "mV" Vector__XXX
 SG_ cell_vol48 : 48|16@1+ (1,0) [0|65535] "mV" Vector__XXX

BO_ 2550202635 vol_msg011: 8 BMS
 SG_ cell_vol41 : 0|16@1+ (1,0) [0|65535] "mV" Vector__XXX
 SG_ cell_vol42 : 16|16@1+ (1,0) [0|65535] "mV" Vector__XXX
 SG_ cell_vol43 : 32|16@1+ (1,0) [0|65535] "mV" Vector__XXX
 SG_ cell_vol44 : 48|16@1+ (1,0) [0|65535] "mV" Vector__XXX

BO_ 2550202634 vol_msg010: 8 BMS
 SG_ cell_vol37 : 0|16@1+ (1,0) [0|65535] "mV" Vector__XXX
 SG_ cell_vol38 : 16|16@1+ (1,0) [0|65535] "mV" Vector__XXX
 SG_ cell_vol39 : 32|16@1+ (1,0) [0|65535] "mV" Vector__XXX
 SG_ cell_vol40 : 48|16@1+ (1,0) [0|65535] "mV" Vector__XXX

BO_ 2550202633 vol_msg009: 8 BMS
 SG_ cell_vol33 : 0|16@1+ (1,0) [0|65535] "mV" Vector__XXX
 SG_ cell_vol34 : 16|16@1+ (1,0) [0|65535] "mV" Vector__XXX
 SG_ cell_vol35 : 32|16@1+ (1,0) [0|65535] "mV" Vector__XXX
 SG_ cell_vol36 : 48|16@1+ (1,0) [0|65535] "mV" Vector__XXX

BO_ 2550202632 vol_msg008: 8 BMS
 SG_ cell_vol29 : 0|16@1+ (1,0) [0|65535] "mV" Vector__XXX
 SG_ cell_vol30 : 16|16@1+ (1,0) [0|65535] "mV" Vector__XXX
 SG_ cell_vol31 : 32|16@1+ (1,0) [0|65535] "mV" Vector__XXX
 SG_ cell_vol32 : 48|16@1+ (1,0) [0|65535] "mV" Vector__XXX

BO_ 2550202631 vol_msg007: 8 BMS
 SG_ cell_vol25 : 0|16@1+ (1,0) [0|65535] "mV" Vector__XXX
 SG_ cell_vol26 : 16|16@1+ (1,0) [0|65535] "mV" Vector__XXX
 SG_ cell_vol27 : 32|16@1+ (1,0) [0|65535] "mV" Vector__XXX
 SG_ cell_vol28 : 48|16@1+ (1,0) [0|65535] "mV" Vector__XXX

BO_ 2550202630 vol_msg006: 8 BMS
 SG_ cell_vol21 : 0|16@1+ (1,0) [0|65535] "mV" Vector__XXX
 SG_ cell_vol22 : 16|16@1+ (1,0) [0|65535] "mV" Vector__XXX
 SG_ cell_vol23 : 32|16@1+ (1,0) [0|65535] "mV" Vector__XXX
 SG_ cell_vol24 : 48|16@1+ (1,0) [0|65535] "mV" Vector__XXX

BO_ 2550202629 vol_msg005: 8 BMS
 SG_ cell_vol17 : 0|16@1+ (1,0) [0|65535] "mV" Vector__XXX
 SG_ cell_vol18 : 16|16@1+ (1,0) [0|65535] "mV" Vector__XXX
 SG_ cell_vol19 : 32|16@1+ (1,0) [0|65535] "mV" Vector__XXX
 SG_ cell_vol20 : 48|16@1+ (1,0) [0|65535] "mV" Vector__XXX

BO_ 2550202628 vol_msg004: 8 BMS
 SG_ cell_vol13 : 0|16@1+ (1,0) [0|65535] "mV" Vector__XXX
 SG_ cell_vol14 : 16|16@1+ (1,0) [0|65535] "mV" Vector__XXX
 SG_ cell_vol15 : 32|16@1+ (1,0) [0|65535] "mV" Vector__XXX
 SG_ cell_vol16 : 48|16@1+ (1,0) [0|65535] "mV" Vector__XXX

BO_ 2550202627 vol_msg003: 8 BMS
 SG_ cell_vol9 : 0|16@1+ (1,0) [0|65535] "mV" Vector__XXX
 SG_ cell_vol10 : 16|16@1+ (1,0) [0|65535] "mV" Vector__XXX
 SG_ cell_vol11 : 32|16@1+ (1,0) [0|65535] "mV" Vector__XXX
 SG_ cell_vol12 : 48|16@1+ (1,0) [0|65535] "mV" Vector__XXX

BO_ 2550202626 vol_msg002: 8 BMS
 SG_ cell_vol5 : 0|16@1+ (1,0) [0|65535] "mV" Vector__XXX
 SG_ cell_vol6 : 16|16@1+ (1,0) [0|65535] "mV" Vector__XXX
 SG_ cell_vol7 : 32|16@1+ (1,0) [0|65535] "mV" Vector__XXX
 SG_ cell_vol8 : 48|16@1+ (1,0) [0|65535] "mV" Vector__XXX

BO_ 2550202625 vol_msg001: 8 BMS
 SG_ cell_vol1 : 0|16@1+ (1,0) [0|65535] "mV" Vector__XXX
 SG_ cell_vol2 : 16|16@1+ (1,0) [0|65535] "mV" Vector__XXX
 SG_ cell_vol3 : 32|16@1+ (1,0) [0|65535] "mV" Vector__XXX
 SG_ cell_vol4 : 48|16@1+ (1,0) [0|65535] "mV" Vector__XXX

BO_ 2550202377 important_msg09: 8 BMS
 SG_ Day_chg_eng : 32|32@1+ (0.01,0) [0|42949672.95] "KWh" Vector__XXX
 SG_ Day_dchg_eng : 0|32@1+ (0.01,0) [0|42949672.95] "KWh" Vector__XXX

BO_ 2550202368 control_msg01: 8 Upper
 SG_ op_value : 8|8@1+ (1,0) [0|255] "" Vector__XXX
 SG_ op_type : 0|8@1+ (1,0) [0|255] "" Vector__XXX

BO_ 2550202381 important_msg13: 8 BMS
 SG_ SOE : 48|16@1+ (0.1,0) [0|6553.5] "%" Vector__XXX
 SG_ left_eng : 32|16@1+ (0.1,0) [0|6553.5] "kWh" Vector__XXX
 SG_ total_eng : 16|16@1+ (0.1,0) [0|6553.5] "kWh" Vector__XXX
 SG_ normal_eng : 0|16@1+ (0.1,0) [0|6553.5] "kWh" Vector__XXX

BO_ 2550202380 important_msg12: 8 BMS
 SG_ SOE_04 : 48|8@1+ (0.4,0) [0|102] "%" Vector__XXX
 SG_ left_cap : 32|16@1+ (0.1,0) [0|6553.5] "AH" Vector__XXX
 SG_ total_cap : 16|16@1+ (0.1,0) [0|6553.5] "AH" Vector__XXX
 SG_ normal_cap : 0|16@1+ (0.1,0) [0|6553.5] "AH" Vector__XXX

BO_ 2550202379 important_msg11: 8 BMS
 SG_ supply_vol : 48|16@1+ (0.001,0) [0|65.535] "V" Vector__XXX
 SG_ HV3 : 32|16@1+ (0.1,0) [0|6553.5] "V" Vector__XXX
 SG_ HV2 : 16|16@1+ (0.1,0) [0|6553.5] "V" Vector__XXX
 SG_ sum_vol : 0|16@1+ (0.1,0) [0|6553.5] "V" Vector__XXX

BO_ 2550202378 important_msg10: 8 BMS
 SG_ sw_version8 : 56|8@1+ (1,0) [0|255] "" Vector__XXX
 SG_ sw_version7 : 48|8@1+ (1,0) [0|255] "" Vector__XXX
 SG_ sw_version6 : 40|8@1+ (1,0) [0|255] "" Vector__XXX
 SG_ sw_version5 : 32|8@1+ (1,0) [0|255] "" Vector__XXX
 SG_ sw_version4 : 24|8@1+ (1,0) [0|255] "" Vector__XXX
 SG_ sw_version3 : 16|8@1+ (1,0) [0|255] "" Vector__XXX
 SG_ sw_version2 : 8|8@1+ (1,0) [0|255] "" Vector__XXX
 SG_ sw_version1 : 0|8@1+ (1,0) [0|255] "" Vector__XXX

BO_ 2550202376 important_msg08: 8 BMS
 SG_ total_chg_eng : 32|32@1+ (0.01,0) [0|42949672.95] "KWh" Vector__XXX
 SG_ total_dchg_eng : 0|32@1+ (0.01,0) [0|42949672.95] "KWh" Vector__XXX

BO_ 2550202375 important_msg07: 8 BMS
 SG_ allow_chg_eng : 48|16@1+ (0.1,0) [0|6553.5] "KWh" Vector__XXX
 SG_ allow_dchg_eng : 32|16@1+ (0.1,0) [0|6553.5] "KWh" Vector__XXX
 SG_ max_chg_power : 16|16@1+ (0.1,0) [0|6553.5] "KW" Vector__XXX
 SG_ max_dchg_power : 0|16@1+ (0.1,0) [0|6553.5] "KW" Vector__XXX

BO_ 2550202374 important_msg06: 8 BMS
 SG_ lpv : 46|2@1+ (1,0) [0|3] "" Vector__XXX
 SG_ hpv : 44|2@1+ (1,0) [0|3] "" Vector__XXX
 SG_ temp_out_contrl : 62|2@1+ (1,0) [0|3] "" Vector__XXX
 SG_ pipe_leakage_flt : 60|2@1+ (1,0) [0|3] "" Vector__XXX
 SG_ incan_rcv_flt : 43|1@1+ (1,0) [0|1] "" Vector__XXX
 SG_ current_comm_err : 40|1@1+ (1,0) [0|1] "" Vector__XXX
 SG_ lsoc : 58|2@1+ (1,0) [0|3] "" Vector__XXX
 SG_ temp_rise : 56|2@1+ (1,0) [0|3] "" Vector__XXX
 SG_ stop_err : 48|1@1+ (1,0) [0|1] "" Vector__XXX
 SG_ bams_comm_flt : 42|1@1+ (1,0) [0|1] "" Vector__XXX
 SG_ bmu_comm_flt : 41|1@1+ (1,0) [0|1] "" Vector__XXX
 SG_ fuse_err : 38|2@1+ (1,0) [0|3] "" Vector__XXX
 SG_ temp_err : 37|1@1+ (1,0) [0|1] "" Vector__XXX
 SG_ cell_err : 36|1@1+ (1,0) [0|1] "" Vector__XXX
 SG_ disable_chg : 35|1@1+ (1,0) [0|1] "" Vector__XXX
 SG_ disable_dchg : 34|1@1+ (1,0) [0|1] "" Vector__XXX
 SG_ NRelay_err : 33|1@1+ (1,0) [0|1] "" Vector__XXX
 SG_ PRelay_err : 32|1@1+ (1,0) [0|1] "" Vector__XXX
 SG_ breaker_sts : 24|8@1+ (1,0) [0|255] "" Vector__XXX
 SG_ dtv : 22|2@1+ (1,0) [0|3] "" Vector__XXX
 SG_ linsu : 20|2@1+ (1,0) [0|3] "" Vector__XXX
 SG_ dt : 18|2@1+ (1,0) [0|3] "" Vector__XXX
 SG_ dv : 16|2@1+ (1,0) [0|3] "" Vector__XXX
 SG_ dc : 14|2@1+ (1,0) [0|3] "" Vector__XXX
 SG_ cc : 12|2@1+ (1,0) [0|3] "" Vector__XXX
 SG_ ht : 10|2@1+ (1,0) [0|3] "" Vector__XXX
 SG_ lt : 8|2@1+ (1,0) [0|3] "" Vector__XXX
 SG_ ltv : 6|2@1+ (1,0) [0|3] "" Vector__XXX
 SG_ lv : 4|2@1+ (1,0) [0|3] "" Vector__XXX
 SG_ htv : 2|2@1+ (1,0) [0|3] "" Vector__XXX
 SG_ hv : 0|2@1+ (1,0) [0|3] "" Vector__XXX

BO_ 2550202373 important_msg05: 8 BMS
 SG_ N_insu : 48|16@1+ (1,0) [0|65535] "KΩ" Vector__XXX
 SG_ min_temp_id1 : 32|16@1+ (1,0) [0|65535] "" Vector__XXX
 SG_ min_temp1 : 24|8@1+ (1,-40) [-40|215] "℃" Vector__XXX
 SG_ max_temp_id1 : 8|16@1+ (1,0) [0|65535] "" Vector__XXX
 SG_ max_temp1 : 0|8@1+ (1,-40) [-40|215] "℃" Vector__XXX

BO_ 2550202372 important_msg04: 8 BMS
 SG_ P_insu : 48|16@1+ (1,0) [0|65535] "KΩ" Vector__XXX
 SG_ min_temp_id : 32|16@1+ (1,0) [0|65535] "" Vector__XXX
 SG_ min_temp : 24|8@1+ (1,-40) [-40|215] "℃" Vector__XXX
 SG_ max_temp_id : 8|16@1+ (1,0) [0|65535] "" Vector__XXX
 SG_ max_temp : 0|8@1+ (1,-40) [-40|215] "℃" Vector__XXX

BO_ 2550202371 important_msg03: 8 BMS
 SG_ min_vol_id1 : 48|16@1+ (1,0) [0|65535] "" Vector__XXX
 SG_ min_vol1 : 32|16@1+ (1,0) [0|65535] "mV" Vector__XXX
 SG_ max_vol_id1 : 16|16@1+ (1,0) [0|65535] "" Vector__XXX
 SG_ max_vol1 : 0|16@1+ (1,0) [0|65535] "mV" Vector__XXX

BO_ 2550202370 important_msg02: 8 BMS
 SG_ min_vol_id : 48|16@1+ (1,0) [0|65535] "" Vector__XXX
 SG_ min_vol : 32|16@1+ (1,0) [0|65535] "mV" Vector__XXX
 SG_ max_vol_id : 16|16@1+ (1,0) [0|65535] "" Vector__XXX
 SG_ max_vol : 0|16@1+ (1,0) [0|65535] "mV" Vector__XXX

BO_ 2550202369 important_msg01: 8 BMS
 SG_ ccu_life : 56|8@1+ (1,0) [0|255] "" Vector__XXX
 SG_ SOH : 48|8@1+ (0.4,0) [0|102] "%" Vector__XXX
 SG_ current : 32|16@1+ (0.1,-3200) [-3200|3353.5] "A" Vector__XXX
 SG_ total_vol : 16|16@1+ (0.1,0) [0|6553.5] "V" Vector__XXX
 SG_ SOC : 8|8@1+ (0.4,0) [0|102] "%" Vector__XXX
 SG_ NRelay_sts : 5|1@1+ (1,0) [0|1] "" Vector__XXX
 SG_ alarm_level : 3|2@1+ (1,0) [0|3] "" Vector__XXX
 SG_ PRelay_sts : 2|1@1+ (1,0) [0|1] "" Vector__XXX
 SG_ sys_status : 0|2@1+ (1,0) [0|3] "" Vector__XXX

CM_ SG_ 2550203137 pack_vol4 "单包4总压";
CM_ SG_ 2550203137 pack_vol3 "单包3总压";
CM_ SG_ 2550203137 pack_vol2 "单包2总压";
CM_ SG_ 2550203137 pack_vol1 "单包1总压";
CM_ SG_ 2550202383 bmu_err_id "故障从机位置";
CM_ SG_ 2550202383 DO_status "DO状态";
CM_ SG_ 2550202383 DI_status "DI状态";
CM_ SG_ 2550202377 Day_chg_eng "当天累计充电电量";
CM_ SG_ 2550202377 Day_dchg_eng "当天累计放电电量";
CM_ SG_ 2550202368 op_value "控制值";
CM_ SG_ 2550202368 op_type "控制类型";
CM_ SG_ 2550202381 SOE "SOE(精度0.1)";
CM_ SG_ 2550202381 left_eng "电池组剩余能量";
CM_ SG_ 2550202381 total_eng "电池组总能量";
CM_ SG_ 2550202381 normal_eng "电池组标称能量";
CM_ SG_ 2550202380 SOE_04 "SOE(精度0.4)";
CM_ SG_ 2550202380 left_cap "电池组剩余容量";
CM_ SG_ 2550202380 total_cap "电池组总容量";
CM_ SG_ 2550202380 normal_cap "电池组标志容量";
CM_ SG_ 2550202379 supply_vol "BMS供电电压";
CM_ SG_ 2550202379 HV3 "后端电压HV3";
CM_ SG_ 2550202379 HV2 "后端电压HV2";
CM_ SG_ 2550202379 sum_vol "电池组累计总压";
CM_ SG_ 2550202378 sw_version8 "软件版本号8";
CM_ SG_ 2550202378 sw_version7 "软件版本号7";
CM_ SG_ 2550202378 sw_version6 "软件版本号6";
CM_ SG_ 2550202378 sw_version5 "软件版本号5";
CM_ SG_ 2550202378 sw_version4 "软件版本号4";
CM_ SG_ 2550202378 sw_version3 "软件版本号3";
CM_ SG_ 2550202378 sw_version2 "软件版本号2";
CM_ SG_ 2550202378 sw_version1 "软件版本号1";
CM_ SG_ 2550202376 total_chg_eng "累计充电电量";
CM_ SG_ 2550202376 total_dchg_eng "累计放电电量";
CM_ SG_ 2550202375 allow_chg_eng "可充电量";
CM_ SG_ 2550202375 allow_dchg_eng "可放电量";
CM_ SG_ 2550202375 max_chg_power "最大充电功率";
CM_ SG_ 2550202375 max_dchg_power "最大放电功率";
CM_ SG_ 2550202374 lpv "单包欠压报警";
CM_ SG_ 2550202374 hpv "单包过压报警";
CM_ SG_ 2550202374 temp_out_contrl "热失控故障";
CM_ SG_ 2550202374 pipe_leakage_flt "管路漏液故障";
CM_ SG_ 2550202374 incan_rcv_flt "INCAN接收异常";
CM_ SG_ 2550202374 current_comm_err "电流采集故障";
CM_ SG_ 2550202374 lsoc "SOC低报警";
CM_ SG_ 2550202374 temp_rise "温升报警";
CM_ SG_ 2550202374 stop_err "急停故障";
CM_ SG_ 2550202374 bams_comm_flt "三级通信异常";
CM_ SG_ 2550202374 bmu_comm_flt "主从通信异常";
CM_ SG_ 2550202374 fuse_err "熔丝故障";
CM_ SG_ 2550202374 temp_err "温感采集线脱落";
CM_ SG_ 2550202374 cell_err "电压采集线脱落";
CM_ SG_ 2550202374 disable_chg "禁止充电";
CM_ SG_ 2550202374 disable_dchg "禁止放电";
CM_ SG_ 2550202374 NRelay_err "总负继电器故障";
CM_ SG_ 2550202374 PRelay_err "总正继电器故障";
CM_ SG_ 2550202374 breaker_sts "断路器状态";
CM_ SG_ 2550202374 dtv "采集总压与累计总压不一致报警";
CM_ SG_ 2550202374 linsu "绝缘低报警";
CM_ SG_ 2550202374 dt "单体温差报警";
CM_ SG_ 2550202374 dv "单体压差报警";
CM_ SG_ 2550202374 dc "放电过流报警";
CM_ SG_ 2550202374 cc "充电过流报警";
CM_ SG_ 2550202374 ht "单体高温报警";
CM_ SG_ 2550202374 lt "单体低温报警";
CM_ SG_ 2550202374 ltv "整组欠压报警";
CM_ SG_ 2550202374 lv "单体欠压报警";
CM_ SG_ 2550202374 htv "整租过压报警";
CM_ SG_ 2550202374 hv "单体过压报警";
CM_ SG_ 2550202373 N_insu "负对地绝缘阻值";
CM_ SG_ 2550202373 min_temp_id1 "次低单体温度编号";
CM_ SG_ 2550202373 min_temp1 "次低单体温度";
CM_ SG_ 2550202373 max_temp_id1 "次高单体温度编号";
CM_ SG_ 2550202373 max_temp1 "次高单体温度";
CM_ SG_ 2550202372 P_insu "正对地绝缘阻值";
CM_ SG_ 2550202372 min_temp_id "最低单体温度编号";
CM_ SG_ 2550202372 min_temp "最低单体温度";
CM_ SG_ 2550202372 max_temp_id "最高单体温度编号";
CM_ SG_ 2550202372 max_temp "最高单体温度";
CM_ SG_ 2550202371 min_vol_id1 "次低单体电压编号";
CM_ SG_ 2550202371 min_vol1 "次低单体电压";
CM_ SG_ 2550202371 max_vol_id1 "次高单体电压编号";
CM_ SG_ 2550202371 max_vol1 "次高单体电压";
CM_ SG_ 2550202370 min_vol_id "最低单体电压编号";
CM_ SG_ 2550202370 min_vol "最低单体电压";
CM_ SG_ 2550202370 max_vol_id "最高单体电压编号";
CM_ SG_ 2550202370 max_vol "最高单体电压";
CM_ SG_ 2550202369 ccu_life "心跳信号";
CM_ SG_ 2550202369 SOH "SOH";
CM_ SG_ 2550202369 current "电池组总电流";
CM_ SG_ 2550202369 total_vol "电池组总压";
CM_ SG_ 2550202369 SOC "SOC";
CM_ SG_ 2550202369 NRelay_sts "主负继电器状态";
CM_ SG_ 2550202369 alarm_level "最高故障等级";
CM_ SG_ 2550202369 PRelay_sts "主正继电器状态";
CM_ SG_ 2550202369 sys_status "系统状态";
BA_DEF_ SG_  "GenSigSendType" ENUM  "Cyclic","OnWrite","OnWriteWithRepetition","OnChange","OnChangeWithRepetition","IfActive","IfActiveWithRepetition","NoSigSendType";
BA_DEF_ BO_  "GenMsgCycleTime" INT 0 0;
BA_DEF_ BO_  "GenMsgSendType" ENUM  "Cyclic","not_used","not_used","not_used","not_used","Cyclic","not_used","IfActive","NoMsgSendType";
BA_DEF_ BU_  "NmStationAddress" HEX 0 0;
BA_DEF_  "DBName" STRING ;
BA_DEF_  "BusType" STRING ;
BA_DEF_DEF_  "GenSigSendType" "Cyclic";
BA_DEF_DEF_  "GenMsgCycleTime" 0;
BA_DEF_DEF_  "GenMsgSendType" "NoMsgSendType";
BA_DEF_DEF_  "NmStationAddress" 0;
BA_DEF_DEF_  "DBName" "";
BA_DEF_DEF_  "BusType" "CAN";
BA_ "DBName" "ccu";
BA_ "NmStationAddress" BU_ Upper 1;
BA_ "GenMsgSendType" BO_ 2550202881 0;
BA_ "GenMsgSendType" BO_ 2550202377 0;
BA_ "GenMsgCycleTime" BO_ 2550202377 500;
BA_ "GenMsgSendType" BO_ 2550202368 7;
BA_ "GenMsgSendType" BO_ 2550202381 0;
BA_ "GenMsgCycleTime" BO_ 2550202381 500;
BA_ "GenMsgSendType" BO_ 2550202380 0;
BA_ "GenMsgCycleTime" BO_ 2550202380 500;
BA_ "GenMsgSendType" BO_ 2550202379 0;
BA_ "GenMsgCycleTime" BO_ 2550202379 500;
BA_ "GenMsgSendType" BO_ 2550202378 0;
BA_ "GenMsgCycleTime" BO_ 2550202378 500;
BA_ "GenMsgSendType" BO_ 2550202376 0;
BA_ "GenMsgCycleTime" BO_ 2550202376 500;
BA_ "GenMsgSendType" BO_ 2550202375 0;
BA_ "GenMsgCycleTime" BO_ 2550202375 500;
BA_ "GenMsgSendType" BO_ 2550202374 0;
BA_ "GenMsgCycleTime" BO_ 2550202374 500;
BA_ "GenMsgSendType" BO_ 2550202373 0;
BA_ "GenMsgCycleTime" BO_ 2550202373 500;
BA_ "GenMsgSendType" BO_ 2550202372 0;
BA_ "GenMsgCycleTime" BO_ 2550202372 500;
BA_ "GenMsgSendType" BO_ 2550202371 0;
BA_ "GenMsgCycleTime" BO_ 2550202371 500;
BA_ "GenMsgSendType" BO_ 2550202370 0;
BA_ "GenMsgCycleTime" BO_ 2550202370 500;
BA_ "GenMsgSendType" BO_ 2550202369 0;
BA_ "GenMsgCycleTime" BO_ 2550202369 200;
VAL_ 2550202368 op_value 1 "闭合" 0 "断开" ;
VAL_ 2550202368 op_type 132 "操作断路器" 129 "操作继电器" ;
VAL_ 2550202374 lpv 3 "三级告警" 2 "二级告警" 1 "一级故障" 0 "正常" ;
VAL_ 2550202374 hpv 3 "三级告警" 2 "二级告警" 1 "一级故障" 0 "正常" ;
VAL_ 2550202374 lsoc 3 "三级告警" 2 "二级告警" 1 "一级故障" 0 "正常" ;
VAL_ 2550202374 temp_rise 3 "三级告警" 2 "二级告警" 1 "一级故障" 0 "正常" ;
VAL_ 2550202374 stop_err 1 "故障" 0 "正常" ;
VAL_ 2550202374 bams_comm_flt 1 "故障" 0 "正常" ;
VAL_ 2550202374 bmu_comm_flt 1 "故障" 0 "正常" ;
VAL_ 2550202374 fuse_err 1 "故障" 0 "正常" ;
VAL_ 2550202374 temp_err 1 "故障" 0 "正常" ;
VAL_ 2550202374 cell_err 1 "故障" 0 "正常" ;
VAL_ 2550202374 disable_chg 1 "禁止" 0 "允许" ;
VAL_ 2550202374 disable_dchg 1 "禁止" 0 "允许" ;
VAL_ 2550202374 NRelay_err 1 "故障" 0 "正常" ;
VAL_ 2550202374 PRelay_err 1 "故障" 0 "正常" ;
VAL_ 2550202374 breaker_sts 1 "闭合" 0 "断开" ;
VAL_ 2550202374 dtv 1 "故障" 0 "正常" ;
VAL_ 2550202374 linsu 3 "三级告警" 2 "二级告警" 1 "一级故障" 0 "正常" ;
VAL_ 2550202374 dt 3 "三级告警" 2 "二级告警" 1 "一级故障" 0 "正常" ;
VAL_ 2550202374 dv 3 "三级告警" 2 "二级告警" 1 "一级故障" 0 "正常" ;
VAL_ 2550202374 dc 3 "三级告警" 2 "二级告警" 1 "一级故障" 0 "正常" ;
VAL_ 2550202374 cc 3 "三级告警" 2 "二级告警" 1 "一级故障" 0 "正常" ;
VAL_ 2550202374 ht 3 "三级告警" 2 "二级告警" 1 "一级故障" 0 "正常" ;
VAL_ 2550202374 lt 3 "三级告警" 2 "二级告警" 1 "一级故障" 0 "正常" ;
VAL_ 2550202374 ltv 3 "三级告警" 2 "二级告警" 1 "一级故障" 0 "正常" ;
VAL_ 2550202374 lv 3 "三级告警" 2 "二级告警" 1 "一级故障" 0 "正常" ;
VAL_ 2550202374 htv 3 "三级告警" 2 "二级告警" 1 "一级故障" 0 "正常" ;
VAL_ 2550202374 hv 3 "三级告警" 2 "二级告警" 1 "一级故障" 0 "正常" ;
VAL_ 2550202369 NRelay_sts 1 "闭合" 0 "断开" ;
VAL_ 2550202369 alarm_level 3 "三级告警" 2 "二级告警" 1 "一级故障" 0 "正常" ;
VAL_ 2550202369 PRelay_sts 1 "闭合" 0 "断开" ;
VAL_ 2550202369 sys_status 2 "充电" 1 "放电" 0 "空闲" ;
